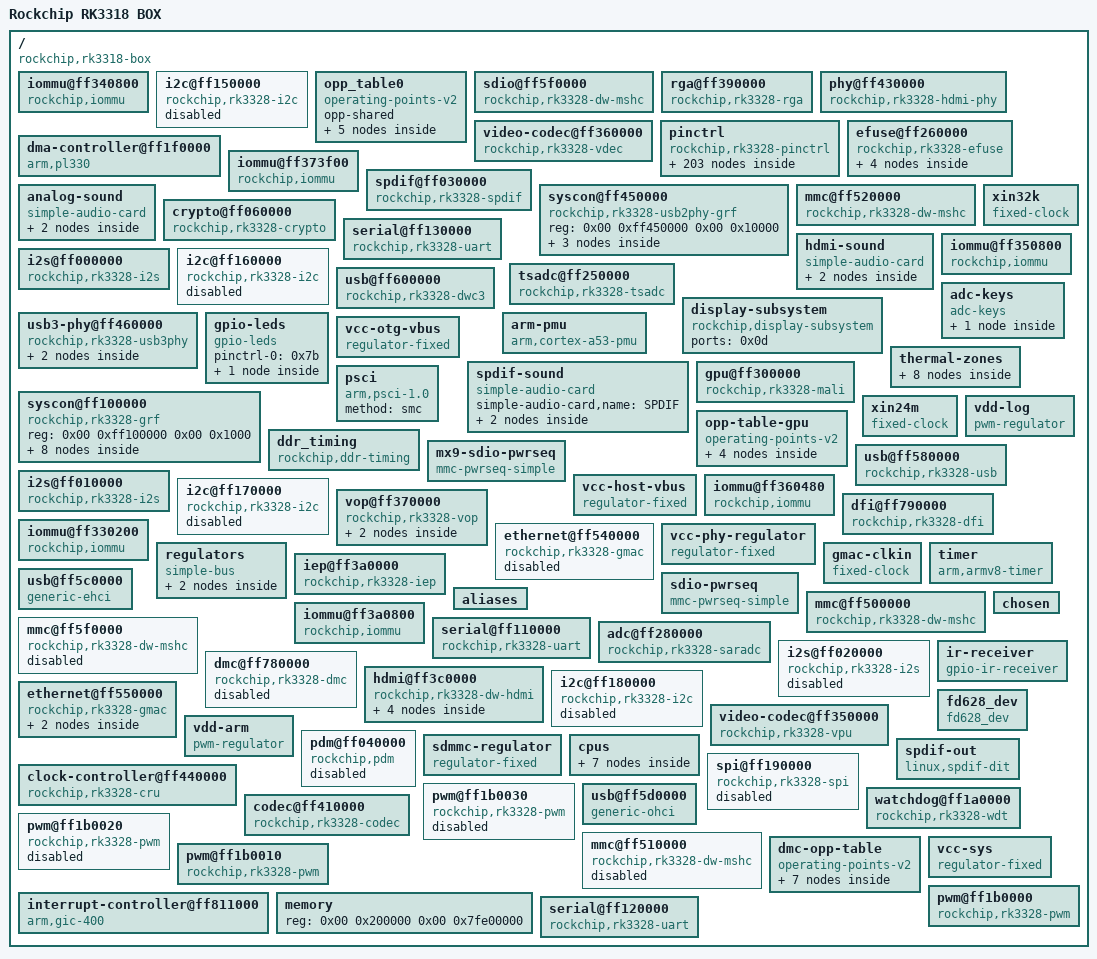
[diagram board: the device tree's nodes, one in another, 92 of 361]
/dts-v1/;

/ {
	#address-cells = <0x02>;
	model = "Rockchip RK3318 BOX";
	serial-number = "0ee56abe064fdcdd";
	#size-cells = <0x02>;
	interrupt-parent = <0x01>;
	compatible = "rockchip,rk3318-box\0rockchip,rk3328-box\0rockchip,rk3328";

	iommu@ff340800 {
		clock-names = "aclk\0iface";
		interrupts = <0x00 0x62 0x04>;
		clocks = <0x02 0x8f 0x02 0x146>;
		#iommu-cells = <0x00>;
		compatible = "rockchip,iommu";
		status = "okay";
		reg = <0x00 0xff340800 0x00 0x40>;
		phandle = <0x9a>;
	};

	i2c@ff150000 {
		pinctrl-names = "default";
		#address-cells = <0x01>;
		pinctrl-0 = <0x27>;
		clock-names = "i2c\0pclk";
		interrupts = <0x00 0x24 0x04>;
		clocks = <0x02 0x37 0x02 0xcd>;
		#size-cells = <0x00>;
		compatible = "rockchip,rk3328-i2c\0rockchip,rk3399-i2c";
		status = "disabled";
		reg = <0x00 0xff150000 0x00 0x1000>;
		phandle = <0x89>;
	};

	opp_table0 {
		opp-shared;
		compatible = "operating-points-v2";
		phandle = <0x04>;

		opp-1200000000 {
			opp-microvolt = <0x124f80>;
			opp-hz = <0x00 0x47868c00>;
			status = "disabled";
			clock-latency-ns = <0x9c40>;
		};

		opp-1008000000 {
			opp-microvolt = <0x10c8e0>;
			opp-hz = <0x00 0x3c14dc00>;
			clock-latency-ns = <0x9c40>;
		};

		opp-1296000000 {
			opp-microvolt = <0x137478>;
			opp-hz = <0x00 0x4d3f6400>;
			status = "disabled";
			clock-latency-ns = <0x9c40>;
		};

		opp-816000000 {
			opp-microvolt = <0xf4240>;
			opp-hz = <0x00 0x30a32c00>;
			clock-latency-ns = <0x9c40>;
		};

		opp-600000000 {
			opp-microvolt = <0xe7ef0>;
			opp-hz = <0x00 0x23c34600>;
			opp-suspend;
			clock-latency-ns = <0x9c40>;
		};
	};

	sdio@ff5f0000 {
		fifo-depth = <0x100>;
		pinctrl-names = "default";
		#address-cells = <0x01>;
		supports-sdio;
		pinctrl-0 = <0x108 0x109 0x10a 0x10b>;
		clock-names = "biu\0ciu\0ciu-drive\0ciu-sample";
		cap-sd-highspeed;
		bus-width = <0x04>;
		non-removable;
		resets = <0x02 0x68>;
		cap-sdio-irq;
		interrupts = <0x00 0x04 0x04>;
		clocks = <0x02 0x140 0x02 0x1f 0x02 0x4d 0x02 0x51>;
		num-slots = <0x01>;
		#size-cells = <0x00>;
		keep-power-in-suspend;
		compatible = "rockchip,rk3328-dw-mshc\0rockchip,rk3288-dw-mshc";
		status = "okay";
		disable-wp;
		mmc-pwrseq = <0x107>;
		reg = <0x00 0xff5f0000 0x00 0x4000>;
		phandle = <0x103>;
		max-frequency = <0x8f0d180>;
		reset-names = "reset";
	};

	rga@ff390000 {
		clock-names = "aclk\0hclk\0sclk";
		resets = <0x02 0x88 0x02 0x8a 0x02 0x8b>;
		interrupts = <0x00 0x21 0x04>;
		clocks = <0x02 0x9a 0x02 0x154 0x02 0x45>;
		compatible = "rockchip,rk3328-rga\0rockchip,rk3399-rga";
		reg = <0x00 0xff390000 0x00 0x1000>;
		phandle = <0x9e>;
		reset-names = "core\0axi\0ahb";
	};

	phy@ff430000 {
		nvmem-cells = <0x4b>;
		clock-output-names = "hdmi_phy";
		clock-names = "sysclk\0refoclk\0refpclk";
		interrupts = <0x00 0x53 0x04>;
		clocks = <0x02 0xe4 0x4a 0x02 0x79>;
		#clock-cells = <0x00>;
		#phy-cells = <0x00>;
		compatible = "rockchip,rk3328-hdmi-phy";
		status = "okay";
		nvmem-cell-names = "cpu-version";
		reg = <0x00 0xff430000 0x00 0x10000>;
		phandle = <0x44>;
	};

	video-codec@ff360000 {
		power-domains = <0x3e 0x05>;
		iommus = <0x40>;
		clock-names = "axi\0ahb\0cabac\0core";
		assigned-clocks = <0x02 0x8b 0x02 0x41 0x02 0x42>;
		assigned-clock-rates = <0x17d78400 0x17d78400 0x11e1a300>;
		interrupts = <0x00 0x07 0x04>;
		clocks = <0x02 0x8b 0x02 0x142 0x02 0x41 0x02 0x42>;
		compatible = "rockchip,rk3328-vdec\0rockchip,rk3399-vdec";
		reg = <0x00 0xff360000 0x00 0x480>;
		phandle = <0x9c>;
	};

	pinctrl {
		pinctrl-names = "default";
		#address-cells = <0x02>;
		pinctrl-0 = <0x67>;
		#size-cells = <0x02>;
		compatible = "rockchip,rk3328-pinctrl";
		ranges;
		rockchip,grf = <0x38>;
		phandle = <0xaf>;

		i2c3 {

			i2c3-xfer {
				rockchip,pins = <0x00 0x05 0x02 0x68 0x00 0x06 0x02 0x68>;
				phandle = <0x2a>;
			};

			i2c3-pins {
				rockchip,pins = <0x00 0x05 0x00 0x68 0x00 0x06 0x00 0x68>;
				phandle = <0xb5>;
			};
		};

		clk_32k {

			clk-32k-out {
				rockchip,pins = <0x01 0x1c 0x01 0x68>;
				phandle = <0x67>;
			};
		};

		pcfg-pull-none-12ma {
			drive-strength = <0x0c>;
			bias-disable;
			phandle = <0x6f>;
		};

		ir {

			ir-int {
				rockchip,pins = <0x02 0x02 0x00 0x68>;
				phandle = <0x7d>;
			};
		};

		i2s1 {

			i2s1-lrcktx {
				rockchip,pins = <0x02 0x11 0x01 0x68>;
				phandle = <0xc8>;
			};

			i2s1-lrckrx {
				rockchip,pins = <0x02 0x10 0x01 0x68>;
				phandle = <0xc7>;
			};

			i2s1-sleep {
				rockchip,pins = <0x02 0x0f 0x00 0x69 0x02 0x10 0x00 0x69 0x02 0x11 0x00 0x69 0x02 0x12 0x00 0x69 0x02 0x13 0x00 0x69 0x02 0x14 0x00 0x69 0x02 0x15 0x00 0x69 0x02 0x16 0x00 0x69 0x02 0x17 0x00 0x69>;
				phandle = <0xce>;
			};

			i2s1-mclk {
				rockchip,pins = <0x02 0x0f 0x01 0x68>;
				phandle = <0xc5>;
			};

			i2s1-sdio3 {
				rockchip,pins = <0x02 0x16 0x01 0x68>;
				phandle = <0xcd>;
			};

			i2s1-sdio1 {
				rockchip,pins = <0x02 0x14 0x01 0x68>;
				phandle = <0xcb>;
			};

			i2s1-sdo {
				rockchip,pins = <0x02 0x17 0x01 0x68>;
				phandle = <0xca>;
			};

			i2s1-sdi {
				rockchip,pins = <0x02 0x13 0x01 0x68>;
				phandle = <0xc9>;
			};

			i2s1-sdio2 {
				rockchip,pins = <0x02 0x15 0x01 0x68>;
				phandle = <0xcc>;
			};

			i2s1-sclk {
				rockchip,pins = <0x02 0x12 0x01 0x68>;
				phandle = <0xc6>;
			};
		};

		mx9pro-sdmmc0ext {

			mx9-sdmmc0ext-clk {
				rockchip,pins = <0x03 0x02 0x03 0x104>;
				phandle = <0x108>;
			};

			mx9-sdmmc0ext-dectn {
				rockchip,pins = <0x03 0x01 0x03 0x105>;
				phandle = <0x10a>;
			};

			mx9-sdmmc0ext-bus4 {
				rockchip,pins = <0x03 0x04 0x03 0x105 0x03 0x05 0x03 0x105 0x03 0x06 0x03 0x105 0x03 0x07 0x03 0x105>;
				phandle = <0x10b>;
			};

			mx9-sdmmc0ext-cmd {
				rockchip,pins = <0x03 0x00 0x03 0x105>;
				phandle = <0x109>;
			};
		};

		i2c1 {

			i2c1-xfer {
				rockchip,pins = <0x02 0x04 0x02 0x68 0x02 0x05 0x02 0x68>;
				phandle = <0x28>;
			};
		};

		usb3 {

			usb30-host-drv {
				rockchip,pins = <0x00 0x00 0x00 0x68>;
				phandle = <0x76>;
			};
		};

		gpio@ff230000 {
			gpio-controller;
			interrupts = <0x00 0x35 0x04>;
			clocks = <0x02 0xca>;
			compatible = "rockchip,gpio-bank";
			#interrupt-cells = <0x02>;
			reg = <0x00 0xff230000 0x00 0x100>;
			phandle = <0x7c>;
			#gpio-cells = <0x02>;
			interrupt-controller;
		};

		cif-1 {

			dvp-d2d9-m1 {
				rockchip,pins = <0x03 0x04 0x02 0x68 0x03 0x05 0x02 0x68 0x03 0x06 0x02 0x68 0x03 0x07 0x02 0x68 0x03 0x08 0x02 0x68 0x02 0x10 0x04 0x68 0x02 0x11 0x04 0x68 0x02 0x12 0x04 0x68 0x03 0x01 0x02 0x68 0x03 0x00 0x02 0x68 0x02 0x0f 0x04 0x68 0x03 0x02 0x02 0x68>;
				phandle = <0xf9>;
			};
		};

		spdif-2 {

			spdifm2-tx {
				rockchip,pins = <0x00 0x02 0x02 0x68>;
				phandle = <0xde>;
			};
		};

		pcfg-pull-down-4ma {
			drive-strength = <0x04>;
			bias-pull-down;
			phandle = <0xb1>;
		};

		spi0-2 {

			spi0m2-tx {
				rockchip,pins = <0x03 0x01 0x04 0x6a>;
				phandle = <0x2c>;
			};

			spi0m2-clk {
				rockchip,pins = <0x03 0x00 0x04 0x6a>;
				phandle = <0x2b>;
			};

			spi0m2-rx {
				rockchip,pins = <0x03 0x02 0x04 0x6a>;
				phandle = <0x2d>;
			};

			spi0m2-cs0 {
				rockchip,pins = <0x03 0x08 0x03 0x6a>;
				phandle = <0x2e>;
			};
		};

		pcfg-pull-none-2ma {
			drive-strength = <0x02>;
			bias-disable;
			phandle = <0x71>;
		};

		sdmmc0-0 {

			sdmmc0m0-pwren {
				rockchip,pins = <0x02 0x07 0x01 0x6b>;
				phandle = <0xdf>;
			};

			sdmmc0m0-pin {
				rockchip,pins = <0x02 0x07 0x00 0x6b>;
				phandle = <0xe0>;
			};
		};

		spdif-0 {

			spdifm0-tx {
				rockchip,pins = <0x00 0x1b 0x01 0x68>;
				phandle = <0x13>;
			};
		};

		tsadc_pin {

			tsadc-pin {
				rockchip,pins = <0x02 0x0d 0x00 0x68>;
				phandle = <0xf7>;
			};

			tsadc-int {
				rockchip,pins = <0x02 0x0d 0x02 0x68>;
				phandle = <0xf6>;
			};
		};

		pcfg-pull-down {
			bias-pull-down;
			phandle = <0x72>;
		};

		mx9-pcfg-pull-none {
			bias-disable;
			phandle = <0x106>;
		};

		gmac-1 {

			rgmiim1-pins {
				rockchip,pins = <0x01 0x0c 0x02 0x6c 0x01 0x0d 0x02 0x6e 0x01 0x13 0x02 0x6e 0x01 0x19 0x02 0x6c 0x01 0x15 0x02 0x6e 0x01 0x16 0x02 0x6e 0x01 0x17 0x02 0x6e 0x01 0x0a 0x02 0x6e 0x01 0x0b 0x02 0x6e 0x01 0x08 0x02 0x6c 0x01 0x09 0x02 0x6c 0x01 0x0e 0x02 0x6e 0x01 0x0f 0x02 0x6e 0x01 0x10 0x02 0x6c 0x01 0x11 0x02 0x6c 0x00 0x08 0x01 0x6c 0x00 0x0c 0x01 0x6c 0x00 0x18 0x01 0x6e 0x00 0x10 0x01 0x6c 0x00 0x11 0x01 0x6c 0x00 0x17 0x01 0x6c 0x00 0x16 0x01 0x6c>;
				phandle = <0xf1>;
			};

			rmiim1-pins {
				rockchip,pins = <0x01 0x13 0x02 0x71 0x01 0x19 0x02 0x6f 0x01 0x15 0x02 0x71 0x01 0x18 0x02 0x71 0x01 0x16 0x02 0x71 0x01 0x17 0x02 0x71 0x01 0x0a 0x02 0x71 0x01 0x0b 0x02 0x71 0x01 0x08 0x02 0x6f 0x01 0x09 0x02 0x6f 0x00 0x0b 0x01 0x68 0x00 0x0c 0x01 0x68 0x00 0x18 0x01 0x68 0x00 0x13 0x01 0x68 0x00 0x10 0x01 0x68 0x00 0x11 0x01 0x68>;
				phandle = <0xf2>;
			};
		};

		spi0-0 {

			spi0m0-cs0 {
				rockchip,pins = <0x02 0x0b 0x01 0x6a>;
				phandle = <0xbc>;
			};

			spi0m0-cs1 {
				rockchip,pins = <0x02 0x0c 0x01 0x6a>;
				phandle = <0xbf>;
			};

			spi0m0-clk {
				rockchip,pins = <0x02 0x08 0x01 0x6a>;
				phandle = <0xbb>;
			};

			spi0m0-tx {
				rockchip,pins = <0x02 0x09 0x01 0x6a>;
				phandle = <0xbd>;
			};

			spi0m0-rx {
				rockchip,pins = <0x02 0x0a 0x01 0x6a>;
				phandle = <0xbe>;
			};
		};

		i2s2-0 {

			i2s2m0-mclk {
				rockchip,pins = <0x01 0x15 0x01 0x68>;
				phandle = <0xcf>;
			};

			i2s2m0-lrcktx {
				rockchip,pins = <0x01 0x17 0x01 0x68>;
				phandle = <0xd2>;
			};

			i2s2m0-sdi {
				rockchip,pins = <0x01 0x18 0x01 0x68>;
				phandle = <0xd3>;
			};

			i2s2m0-lrckrx {
				rockchip,pins = <0x01 0x1a 0x01 0x68>;
				phandle = <0xd1>;
			};

			i2s2m0-sleep {
				rockchip,pins = <0x01 0x15 0x00 0x69 0x01 0x16 0x00 0x69 0x01 0x1a 0x00 0x69 0x01 0x17 0x00 0x69 0x01 0x18 0x00 0x69 0x01 0x19 0x00 0x69>;
				phandle = <0xd5>;
			};

			i2s2m0-sclk {
				rockchip,pins = <0x01 0x16 0x01 0x68>;
				phandle = <0xd0>;
			};

			i2s2m0-sdo {
				rockchip,pins = <0x01 0x19 0x01 0x68>;
				phandle = <0xd4>;
			};
		};

		hdmi_i2c {

			hdmii2c-xfer {
				rockchip,pins = <0x00 0x05 0x01 0x68 0x00 0x06 0x01 0x68>;
				phandle = <0x46>;
			};
		};

		gpio@ff240000 {
			gpio-controller;
			interrupts = <0x00 0x36 0x04>;
			clocks = <0x02 0xcb>;
			compatible = "rockchip,gpio-bank";
			#interrupt-cells = <0x02>;
			reg = <0x00 0xff240000 0x00 0x100>;
			phandle = <0x60>;
			#gpio-cells = <0x02>;
			interrupt-controller;
		};

		sdmmc1 {

			sdmmc1-cmd {
				rockchip,pins = <0x01 0x0d 0x01 0x6d>;
				phandle = <0x55>;
			};

			sdmmc1-pins {
				rockchip,pins = <0x01 0x0c 0x00 0x6b 0x01 0x0d 0x00 0x6b 0x01 0x0e 0x00 0x6b 0x01 0x0f 0x00 0x6b 0x01 0x10 0x00 0x6b 0x01 0x11 0x00 0x6b 0x01 0x12 0x00 0x6b 0x01 0x13 0x00 0x6b 0x01 0x14 0x00 0x6b>;
				phandle = <0xec>;
			};

			sdmmc1-bus1 {
				rockchip,pins = <0x01 0x0e 0x01 0x6d>;
				phandle = <0xeb>;
			};

			sdmmc1-clk {
				rockchip,pins = <0x01 0x0c 0x01 0x6c>;
				phandle = <0x56>;
			};

			sdmmc1-bus4 {
				rockchip,pins = <0x01 0x0e 0x01 0x6d 0x01 0x0f 0x01 0x6d 0x01 0x10 0x01 0x6d 0x01 0x11 0x01 0x6d>;
				phandle = <0x54>;
			};

			sdmmc1-pwren {
				rockchip,pins = <0x01 0x12 0x01 0x6d>;
				phandle = <0xe8>;
			};

			sdmmc1-dectn {
				rockchip,pins = <0x01 0x13 0x01 0x6d>;
				phandle = <0xea>;
			};

			sdmmc1-wrprt {
				rockchip,pins = <0x01 0x14 0x01 0x6d>;
				phandle = <0xe9>;
			};
		};

		pcfg-pull-none-8ma {
			drive-strength = <0x08>;
			bias-disable;
			phandle = <0x6c>;
		};

		leds {

			working-led {
				rockchip,pins = <0x02 0x17 0x00 0x71>;
				phandle = <0x7b>;
			};
		};

		pwm1 {

			pwm1-pin {
				rockchip,pins = <0x02 0x05 0x01 0x68>;
				phandle = <0x30>;
			};
		};

		tsadc {

			otp-pin {
				rockchip,pins = <0x02 0x0d 0x00 0x68>;
				phandle = <0x36>;
			};

			otp-out {
				rockchip,pins = <0x02 0x0d 0x01 0x68>;
				phandle = <0x37>;
			};
		};

		pwmir {

			pwmir-pin {
				rockchip,pins = <0x02 0x02 0x01 0x68>;
				phandle = <0x32>;
			};
		};

		uart2-1 {

			uart2m1-xfer {
				rockchip,pins = <0x02 0x00 0x01 0x68 0x02 0x01 0x01 0x6a>;
				phandle = <0x26>;
			};
		};

		uart0 {

			uart0-rts-pin {
				rockchip,pins = <0x01 0x0a 0x00 0x68>;
				phandle = <0xb8>;
			};

			uart0-cts {
				rockchip,pins = <0x01 0x0b 0x01 0x68>;
				phandle = <0x21>;
			};

			uart0-rts {
				rockchip,pins = <0x01 0x0a 0x01 0x68>;
				phandle = <0x22>;
			};

			uart0-xfer {
				rockchip,pins = <0x01 0x09 0x01 0x68 0x01 0x08 0x01 0x6a>;
				phandle = <0x20>;
			};
		};

		emmc {

			emmc-clk {
				rockchip,pins = <0x03 0x15 0x02 0x6f>;
				phandle = <0x57>;
			};

			emmc-bus1 {
				rockchip,pins = <0x00 0x07 0x02 0x70>;
				phandle = <0xef>;
			};

			emmc-bus8 {
				rockchip,pins = <0x00 0x07 0x02 0x70 0x02 0x1c 0x02 0x70 0x02 0x1d 0x02 0x70 0x02 0x1e 0x02 0x70 0x02 0x1f 0x02 0x70 0x03 0x10 0x02 0x70 0x03 0x11 0x02 0x70 0x03 0x12 0x02 0x70>;
				phandle = <0x59>;
			};

			emmc-bus4 {
				rockchip,pins = <0x00 0x07 0x02 0x70 0x02 0x1c 0x02 0x70 0x02 0x1d 0x02 0x70 0x02 0x1e 0x02 0x70>;
				phandle = <0xf0>;
			};

			emmc-pwren {
				rockchip,pins = <0x03 0x16 0x02 0x68>;
				phandle = <0xed>;
			};

			emmc-cmd {
				rockchip,pins = <0x03 0x13 0x02 0x70>;
				phandle = <0x58>;
			};

			emmc-rstnout {
				rockchip,pins = <0x03 0x14 0x02 0x68>;
				phandle = <0xee>;
			};
		};

		pcfg-output-high {
			output-high;
			phandle = <0xb2>;
		};

		pcfg-pull-up {
			phandle = <0x6a>;
			bias-pull-up;
		};

		sdmmc0ext {

			sdmmc0ext-clk {
				rockchip,pins = <0x03 0x02 0x03 0x6e>;
				phandle = <0x61>;
			};

			sdmmc0ext-bus4 {
				rockchip,pins = <0x03 0x04 0x03 0x6b 0x03 0x05 0x03 0x6b 0x03 0x06 0x03 0x6b 0x03 0x07 0x03 0x6b>;
				phandle = <0x64>;
			};

			sdmmc0ext-wrprt {
				rockchip,pins = <0x03 0x03 0x03 0x6b>;
				phandle = <0xe5>;
			};

			sdmmc0ext-pins {
				rockchip,pins = <0x03 0x00 0x00 0x6b 0x03 0x01 0x00 0x6b 0x03 0x02 0x00 0x6b 0x03 0x03 0x00 0x6b 0x03 0x04 0x00 0x6b 0x03 0x05 0x00 0x6b 0x03 0x06 0x00 0x6b 0x03 0x07 0x00 0x6b>;
				phandle = <0xe7>;
			};

			sdmmc0ext-bus1 {
				rockchip,pins = <0x03 0x04 0x03 0x6b>;
				phandle = <0xe6>;
			};

			sdmmc0ext-cmd {
				rockchip,pins = <0x03 0x00 0x03 0x6b>;
				phandle = <0x62>;
			};

			sdmmc0ext-dectn {
				rockchip,pins = <0x03 0x01 0x03 0x6b>;
				phandle = <0x63>;
			};
		};

		mx9-pcfg-pull-up-4ma {
			drive-strength = <0x04>;
			phandle = <0x105>;
			bias-pull-up;
		};

		pcfg-input {
			phandle = <0xb4>;
			input-enable;
		};

		pcfg-pull-up-2ma {
			drive-strength = <0x02>;
			phandle = <0xb0>;
			bias-pull-up;
		};

		i2c2 {

			i2c2-xfer {
				rockchip,pins = <0x02 0x0d 0x01 0x68 0x02 0x0e 0x01 0x68>;
				phandle = <0x29>;
			};
		};

		pmic {

			pmic-int-l {
				rockchip,pins = <0x02 0x06 0x00 0x6a>;
				phandle = <0xfa>;
			};
		};

		pcfg-pull-none {
			bias-disable;
			phandle = <0x68>;
		};

		pcfg-pull-none-4ma {
			drive-strength = <0x04>;
			bias-disable;
			phandle = <0x6e>;
		};

		gpio@ff210000 {
			gpio-controller;
			interrupts = <0x00 0x33 0x04>;
			clocks = <0x02 0xc8>;
			compatible = "rockchip,gpio-bank";
			#interrupt-cells = <0x02>;
			reg = <0x00 0xff210000 0x00 0x100>;
			phandle = <0x74>;
			#gpio-cells = <0x02>;
			interrupt-controller;
		};

		sdio-pwrseq {

			wifi-enable-h {
				rockchip,pins = <0x01 0x12 0x00 0x6e>;
				phandle = <0x7e>;
			};
		};

		pdm-0 {

			pdmm0-sdi3 {
				rockchip,pins = <0x02 0x16 0x02 0x68>;
				phandle = <0x18>;
			};

			pdmm0-sdi1 {
				rockchip,pins = <0x02 0x14 0x02 0x68>;
				phandle = <0x16>;
			};

			pdmm0-sdi2-sleep {
				rockchip,pins = <0x02 0x15 0x00 0x69>;
				phandle = <0x1c>;
			};

			pdmm0-fsync {
				rockchip,pins = <0x02 0x17 0x02 0x68>;
				phandle = <0xb6>;
			};

			pdmm0-sdi3-sleep {
				rockchip,pins = <0x02 0x16 0x00 0x69>;
				phandle = <0x1d>;
			};

			pdmm0-sdi2 {
				rockchip,pins = <0x02 0x15 0x02 0x68>;
				phandle = <0x17>;
			};

			pdmm0-sdi0 {
				rockchip,pins = <0x02 0x13 0x02 0x68>;
				phandle = <0x15>;
			};

			pdmm0-sdi0-sleep {
				rockchip,pins = <0x02 0x13 0x00 0x69>;
				phandle = <0x1a>;
			};

			pdmm0-clk-sleep {
				rockchip,pins = <0x02 0x12 0x00 0x69>;
				phandle = <0x19>;
			};

			pdmm0-clk {
				rockchip,pins = <0x02 0x12 0x02 0x68>;
				phandle = <0x14>;
			};

			pdmm0-fsync-sleep {
				rockchip,pins = <0x02 0x17 0x00 0x69>;
				phandle = <0xb7>;
			};

			pdmm0-sdi1-sleep {
				rockchip,pins = <0x02 0x14 0x00 0x69>;
				phandle = <0x1b>;
			};
		};

		i2c0 {

			i2c0-xfer {
				rockchip,pins = <0x02 0x18 0x01 0x68 0x02 0x19 0x01 0x68>;
				phandle = <0x27>;
			};
		};

		usb2 {

			usb20-host-drv {
				rockchip,pins = <0x00 0x02 0x00 0x68>;
				phandle = <0x78>;
			};
		};

		sdmmc0-1 {

			sdmmc0m1-pwren {
				rockchip,pins = <0x00 0x1e 0x03 0x6b>;
				phandle = <0xe1>;
			};

			sdmmc0m1-pin {
				rockchip,pins = <0x00 0x1e 0x00 0x6b>;
				phandle = <0x75>;
			};
		};

		cif-0 {

			dvp-d2d9-m0 {
				rockchip,pins = <0x03 0x04 0x02 0x68 0x03 0x05 0x02 0x68 0x03 0x06 0x02 0x68 0x03 0x07 0x02 0x68 0x03 0x08 0x02 0x68 0x03 0x09 0x02 0x68 0x03 0x0a 0x02 0x68 0x03 0x0b 0x02 0x68 0x03 0x01 0x02 0x68 0x03 0x00 0x02 0x68 0x03 0x03 0x02 0x68 0x03 0x02 0x02 0x68>;
				phandle = <0xf8>;
			};
		};

		spdif-1 {

			spdifm1-tx {
				rockchip,pins = <0x02 0x11 0x02 0x68>;
				phandle = <0xdd>;
			};
		};

		pcfg-input-high {
			phandle = <0x69>;
			bias-pull-up;
			input-enable;
		};

		pcfg-pull-up-8ma {
			drive-strength = <0x08>;
			phandle = <0x6d>;
			bias-pull-up;
		};

		spi0-1 {

			spi0m1-cs0 {
				rockchip,pins = <0x03 0x1a 0x02 0x6a>;
				phandle = <0xc1>;
			};

			spi0m1-tx {
				rockchip,pins = <0x03 0x19 0x02 0x6a>;
				phandle = <0xc2>;
			};

			spi0m1-rx {
				rockchip,pins = <0x03 0x18 0x02 0x6a>;
				phandle = <0xc3>;
			};

			spi0m1-cs1 {
				rockchip,pins = <0x03 0x1b 0x02 0x6a>;
				phandle = <0xc4>;
			};

			spi0m1-clk {
				rockchip,pins = <0x03 0x17 0x02 0x6a>;
				phandle = <0xc0>;
			};
		};

		mx9-wifi-enable-h {
			rockchip,pins = <0x03 0x08 0x00 0x106>;
			phandle = <0x10c>;
		};

		i2s2-1 {

			i2s2m1-mclk {
				rockchip,pins = <0x01 0x15 0x01 0x68>;
				phandle = <0xd6>;
			};

			i2s2m1-sdo {
				rockchip,pins = <0x03 0x01 0x06 0x68>;
				phandle = <0xdb>;
			};

			i2s2m1-lrcktx {
				rockchip,pins = <0x03 0x08 0x04 0x68>;
				phandle = <0xd9>;
			};

			i2s2m1-sdi {
				rockchip,pins = <0x03 0x02 0x06 0x68>;
				phandle = <0xda>;
			};

			i2sm1-lrckrx {
				rockchip,pins = <0x03 0x08 0x06 0x68>;
				phandle = <0xd8>;
			};

			i2s2m1-sleep {
				rockchip,pins = <0x01 0x15 0x00 0x69 0x03 0x00 0x00 0x69 0x03 0x08 0x00 0x69 0x03 0x02 0x00 0x69 0x03 0x01 0x00 0x69>;
				phandle = <0xdc>;
			};

			i2s2m1-sclk {
				rockchip,pins = <0x03 0x00 0x06 0x68>;
				phandle = <0xd7>;
			};
		};

		pcfg-pull-up-12ma {
			drive-strength = <0x0c>;
			phandle = <0x70>;
			bias-pull-up;
		};

		hdmi_pin {

			hdmi-cec {
				rockchip,pins = <0x00 0x03 0x01 0x68>;
				phandle = <0x45>;
			};

			hdmi-hpd {
				rockchip,pins = <0x00 0x04 0x01 0x72>;
				phandle = <0x47>;
			};
		};

		pcfg-output-low {
			phandle = <0xb3>;
			output-low;
		};

		gmac2phy {

			fephyled-speed10 {
				rockchip,pins = <0x00 0x1e 0x01 0x68>;
				phandle = <0xf3>;
			};

			fephyled-linkm1 {
				rockchip,pins = <0x02 0x18 0x02 0x68>;
				phandle = <0x5d>;
			};

			fephyled-duplex {
				rockchip,pins = <0x00 0x1e 0x02 0x68>;
				phandle = <0xf4>;
			};

			fephyled-rxm1 {
				rockchip,pins = <0x02 0x19 0x02 0x68>;
				phandle = <0x5c>;
			};

			fephyled-txm1 {
				rockchip,pins = <0x02 0x19 0x03 0x68>;
				phandle = <0xf5>;
			};
		};

		pwm2 {

			pwm2-pin {
				rockchip,pins = <0x02 0x06 0x01 0x68>;
				phandle = <0x31>;
			};
		};

		gpio@ff220000 {
			gpio-controller;
			interrupts = <0x00 0x34 0x04>;
			clocks = <0x02 0xc9>;
			compatible = "rockchip,gpio-bank";
			#interrupt-cells = <0x02>;
			reg = <0x00 0xff220000 0x00 0x100>;
			phandle = <0x4d>;
			#gpio-cells = <0x02>;
			interrupt-controller;
		};

		mx9-pcfg-pull-none-4ma {
			drive-strength = <0x04>;
			bias-disable;
			phandle = <0x104>;
		};

		uart1 {

			uart1-cts {
				rockchip,pins = <0x03 0x07 0x04 0x68>;
				phandle = <0x24>;
			};

			uart1-rts-pin {
				rockchip,pins = <0x03 0x05 0x00 0x68>;
				phandle = <0xb9>;
			};

			uart1-rts {
				rockchip,pins = <0x03 0x05 0x04 0x68>;
				phandle = <0x25>;
			};

			uart1-xfer {
				rockchip,pins = <0x03 0x04 0x04 0x68 0x03 0x06 0x04 0x6a>;
				phandle = <0x23>;
			};
		};

		sdmmc0 {

			sdmmc0-pins {
				rockchip,pins = <0x01 0x06 0x00 0x6b 0x01 0x04 0x00 0x6b 0x01 0x05 0x00 0x6b 0x01 0x07 0x00 0x6b 0x01 0x03 0x00 0x6b 0x01 0x02 0x00 0x6b 0x01 0x01 0x00 0x6b 0x01 0x00 0x00 0x6b>;
				phandle = <0xe4>;
			};

			sdmmc0-bus1 {
				rockchip,pins = <0x01 0x00 0x01 0x6d>;
				phandle = <0xe3>;
			};

			sdmmc0-dectn {
				rockchip,pins = <0x01 0x05 0x01 0x6b>;
				phandle = <0x50>;
			};

			sdmmc0-bus4 {
				rockchip,pins = <0x01 0x00 0x01 0x6d 0x01 0x01 0x01 0x6d 0x01 0x02 0x01 0x6d 0x01 0x03 0x01 0x6d>;
				phandle = <0x51>;
			};

			sdmmc0-wrprt {
				rockchip,pins = <0x01 0x07 0x01 0x6b>;
				phandle = <0xe2>;
			};

			sdmmc0-cmd {
				rockchip,pins = <0x01 0x04 0x01 0x6d>;
				phandle = <0x4f>;
			};

			sdmmc0-clk {
				rockchip,pins = <0x01 0x06 0x01 0x6c>;
				phandle = <0x4e>;
			};
		};

		pcfg-pull-up-4ma {
			drive-strength = <0x04>;
			phandle = <0x6b>;
			bias-pull-up;
		};

		pwm0 {

			pwm0-pin {
				rockchip,pins = <0x02 0x04 0x01 0x68>;
				phandle = <0x2f>;
			};
		};

		uart2-0 {

			uart2m0-xfer {
				rockchip,pins = <0x01 0x00 0x02 0x68 0x01 0x01 0x02 0x6a>;
				phandle = <0xba>;
			};
		};

		wireless-wlan {

			sdio-host-wake {
				rockchip,pins = <0x01 0x13 0x00 0x68>;
				phandle = <0xfb>;
			};

			sdio-host-wake-ext {
				rockchip,pins = <0x03 0x01 0x00 0x68>;
				phandle = <0xfc>;
			};
		};
	};

	efuse@ff260000 {
		#address-cells = <0x01>;
		clock-names = "pclk_efuse";
		clocks = <0x02 0x3e>;
		#size-cells = <0x01>;
		compatible = "rockchip,rk3328-efuse";
		rockchip,efuse-size = <0x20>;
		reg = <0x00 0xff260000 0x00 0x50>;
		phandle = <0x95>;

		id@7 {
			reg = <0x07 0x10>;
			phandle = <0x96>;
		};

		cpu-version@1a {
			bits = <0x03 0x03>;
			reg = <0x1a 0x01>;
			phandle = <0x4b>;
		};

		logic-leakage@19 {
			reg = <0x19 0x01>;
			phandle = <0x98>;
		};

		cpu-leakage@17 {
			reg = <0x17 0x01>;
			phandle = <0x97>;
		};
	};

	dma-controller@ff1f0000 {
		clock-names = "apb_pclk";
		interrupts = <0x00 0x00 0x04 0x00 0x01 0x04>;
		clocks = <0x02 0x86>;
		arm,pl330-periph-burst;
		compatible = "arm,pl330\0arm,primecell";
		reg = <0x00 0xff1f0000 0x00 0x4000>;
		phandle = <0x12>;
		#dma-cells = <0x01>;
	};

	iommu@ff373f00 {
		clock-names = "aclk\0iface";
		interrupts = <0x00 0x20 0x04>;
		clocks = <0x02 0x91 0x02 0x13b>;
		#iommu-cells = <0x00>;
		compatible = "rockchip,iommu";
		status = "okay";
		reg = <0x00 0xff373f00 0x00 0x100>;
		phandle = <0x41>;
	};

	spdif@ff030000 {
		pinctrl-names = "default";
		pinctrl-0 = <0x13>;
		clock-names = "mclk\0hclk";
		interrupts = <0x00 0x1d 0x04>;
		clocks = <0x02 0x2e 0x02 0x13a>;
		dma-names = "tx";
		#sound-dai-cells = <0x00>;
		compatible = "rockchip,rk3328-spdif";
		status = "okay";
		reg = <0x00 0xff030000 0x00 0x1000>;
		phandle = <0x10>;
		dmas = <0x12 0x0a>;
	};

	analog-sound {
		simple-audio-card,name = "ANALOG";
		simple-audio-card,format = "i2s";
		compatible = "simple-audio-card";
		status = "okay";
		phandle = <0x7f>;
		simple-audio-card,mclk-fs = <0x100>;

		simple-audio-card,cpu {
			sound-dai = <0x07>;
		};

		simple-audio-card,codec {
			sound-dai = <0x08>;
		};
	};

	syscon@ff450000 {
		#address-cells = <0x01>;
		#size-cells = <0x01>;
		compatible = "rockchip,rk3328-usb2phy-grf\0syscon\0simple-mfd";
		reg = <0x00 0xff450000 0x00 0x10000>;
		phandle = <0xa2>;

		usb2phy@100 {
			clock-output-names = "usb480m_phy";
			clock-names = "phyclk";
			assigned-clocks = <0x02 0x7b>;
			assigned-clock-parents = <0x4c>;
			clocks = <0x4a>;
			#clock-cells = <0x00>;
			compatible = "rockchip,rk3328-usb2phy";
			status = "okay";
			reg = <0x100 0x10>;
			phandle = <0x4c>;

			host-port {
				interrupts = <0x00 0x3e 0x04>;
				#phy-cells = <0x00>;
				status = "okay";
				interrupt-names = "linestate";
				phandle = <0x5f>;
			};

			otg-port {
				interrupts = <0x00 0x3b 0x04 0x00 0x3c 0x04 0x00 0x3d 0x04>;
				#phy-cells = <0x00>;
				status = "okay";
				interrupt-names = "otg-bvalid\0otg-id\0linestate";
				phandle = <0x5e>;
			};
		};
	};

	mmc@ff520000 {
		fifo-depth = <0x100>;
		pinctrl-names = "default";
		pinctrl-0 = <0x57 0x58 0x59>;
		clock-names = "biu\0ciu\0ciu-drive\0ciu-sample";
		vqmmc-supply = <0x1f>;
		bus-width = <0x08>;
		non-removable;
		no-sdio;
		resets = <0x02 0x6f>;
		interrupts = <0x00 0x0e 0x04>;
		clocks = <0x02 0x13f 0x02 0x23 0x02 0x4c 0x02 0x50>;
		num-slots = <0x01>;
		vmmc-supply = <0x1e>;
		no-sd;
		compatible = "rockchip,rk3328-dw-mshc\0rockchip,rk3288-dw-mshc";
		status = "okay";
		disable-wp;
		reg = <0x00 0xff520000 0x00 0x4000>;
		phandle = <0xa6>;
		max-frequency = <0x8f0d180>;
		cap-mmc-highspeed;
		reset-names = "reset";
		supports-emmc;
	};

	crypto@ff060000 {
		clock-names = "hclk_master\0hclk_slave\0sclk";
		resets = <0x02 0x44>;
		interrupts = <0x00 0x1e 0x04>;
		clocks = <0x02 0x150 0x02 0x151 0x02 0x3b>;
		compatible = "rockchip,rk3328-crypto";
		reg = <0x00 0xff060000 0x00 0x4000>;
		phandle = <0xae>;
		reset-names = "crypto-rst";
	};

	serial@ff130000 {
		reg-io-width = <0x04>;
		pinctrl-names = "default";
		pinctrl-0 = <0x26>;
		clock-names = "baudclk\0apb_pclk";
		interrupts = <0x00 0x39 0x04>;
		clocks = <0x02 0x28 0x02 0xd4>;
		compatible = "rockchip,rk3328-uart\0snps,dw-apb-uart";
		status = "okay";
		reg = <0x00 0xff130000 0x00 0x100>;
		phandle = <0x88>;
		reg-shift = <0x02>;
	};

	hdmi-sound {
		simple-audio-card,name = "HDMI";
		simple-audio-card,format = "i2s";
		compatible = "simple-audio-card";
		status = "okay";
		phandle = <0x81>;
		simple-audio-card,mclk-fs = <0x80>;

		simple-audio-card,cpu {
			sound-dai = <0x0e>;
		};

		simple-audio-card,codec {
			sound-dai = <0x0f>;
		};
	};

	i2s@ff000000 {
		clock-names = "i2s_clk\0i2s_hclk";
		interrupts = <0x00 0x1a 0x04>;
		clocks = <0x02 0x29 0x02 0x137>;
		dma-names = "tx\0rx";
		#sound-dai-cells = <0x00>;
		compatible = "rockchip,rk3328-i2s\0rockchip,rk3066-i2s";
		status = "okay";
		reg = <0x00 0xff000000 0x00 0x1000>;
		phandle = <0x0e>;
		dmas = <0x12 0x0b 0x12 0x0c>;
	};

	xin32k {
		clock-output-names = "xin32k";
		#clock-cells = <0x00>;
		clock-frequency = <0x8000>;
		compatible = "fixed-clock";
		phandle = <0xfe>;
	};

	iommu@ff350800 {
		power-domains = <0x3e 0x08>;
		clock-names = "aclk\0iface";
		interrupts = <0x00 0x0b 0x04>;
		clocks = <0x02 0x8f 0x02 0x146>;
		#iommu-cells = <0x00>;
		compatible = "rockchip,iommu";
		status = "okay";
		reg = <0x00 0xff350800 0x00 0x40>;
		phandle = <0x3f>;
	};

	i2c@ff160000 {
		pinctrl-names = "default";
		#address-cells = <0x01>;
		pinctrl-0 = <0x28>;
		clock-names = "i2c\0pclk";
		interrupts = <0x00 0x25 0x04>;
		clocks = <0x02 0x38 0x02 0xce>;
		#size-cells = <0x00>;
		compatible = "rockchip,rk3328-i2c\0rockchip,rk3399-i2c";
		status = "disabled";
		reg = <0x00 0xff160000 0x00 0x1000>;
		phandle = <0x8a>;
	};

	tsadc@ff250000 {
		pinctrl-names = "init\0default\0sleep";
		pinctrl-2 = <0x36>;
		pinctrl-0 = <0x36>;
		clock-names = "tsadc\0apb_pclk";
		rockchip,hw-tshut-polarity = <0x00>;
		assigned-clocks = <0x02 0x24>;
		assigned-clock-rates = <0xc350>;
		resets = <0x02 0x42>;
		interrupts = <0x00 0x3a 0x04>;
		rockchip,hw-tshut-mode = <0x00>;
		clocks = <0x02 0x24 0x02 0xd5>;
		#thermal-sensor-cells = <0x01>;
		compatible = "rockchip,rk3328-tsadc";
		pinctrl-1 = <0x37>;
		status = "okay";
		reg = <0x00 0xff250000 0x00 0x100>;
		phandle = <0x33>;
		reset-names = "tsadc-apb";
		rockchip,hw-tshut-temp = <0x186a0>;
	};

	display-subsystem {
		ports = <0x0d>;
		compatible = "rockchip,display-subsystem";
		status = "okay";
		phandle = <0x80>;
	};

	usb@ff600000 {
		#address-cells = <0x01>;
		snps,dis_enblslpm_quirk;
		phy-names = "usb2-phy\0usb3-phy";
		clock-names = "ref_clk\0suspend_clk\0bus_clk";
		snps,dis-u2-freeclk-exists-quirk;
		phy_type = "utmi_wide";
		snps,dis_u2_susphy_quirk;
		resets = <0x02 0x78>;
		interrupts = <0x00 0x43 0x04>;
		clocks = <0x02 0x60 0x02 0x61 0x02 0x84>;
		#size-cells = <0x00>;
		compatible = "rockchip,rk3328-dwc3\0snps,dwc3";
		snps,dis_u3_susphy_quirk;
		snps,dis-del-phy-power-chg-quirk;
		status = "okay";
		snps,xhci-trb-ent-quirk;
		phys = <0x65 0x66>;
		reg = <0x00 0xff600000 0x00 0x100000>;
		phandle = <0xad>;
		dr_mode = "host";
		reset-names = "usb3-otg";
		snps,dis-tx-ipgap-linecheck-quirk;
	};

	adc-keys {
		io-channels = <0x73 0x00>;
		poll-interval = <0x64>;
		keyup-threshold-microvolt = <0x1b7740>;
		compatible = "adc-keys";
		phandle = <0xfd>;
		io-channel-names = "buttons";

		recovery {
			press-threshold-microvolt = <0x4268>;
			label = "recovery";
			linux,code = <0x168>;
		};
	};

	usb3-phy@ff460000 {
		#address-cells = <0x02>;
		clock-names = "refclk-usb3otg\0usb3phy-otg\0usb3phy-pipe";
		resets = <0x02 0x7d 0x02 0x7e 0x02 0x7f 0x02 0x7c 0x02 0x9e 0x02 0x9f>;
		interrupts = <0x00 0x4b 0x04 0x00 0x4c 0x04 0x00 0x4d 0x04 0x00 0x4e 0x04>;
		clocks = <0x02 0x5f 0x02 0xe0 0x02 0xe1>;
		#size-cells = <0x02>;
		compatible = "rockchip,rk3328-usb3phy";
		ranges;
		status = "okay";
		interrupt-names = "bvalid\0id\0linestate\0rxdet";
		reg = <0x00 0xff460000 0x00 0x10000>;
		phandle = <0xa3>;
		reset-names = "usb3phy-u2-por\0usb3phy-u3-por\0usb3phy-pipe-mac\0usb3phy-utmi-mac\0usb3phy-utmi-apb\0usb3phy-pipe-apb";

		utmi-port@ff470000 {
			#phy-cells = <0x00>;
			compatible = "rockchip,rk3328-usb3phy-utmi";
			status = "okay";
			reg = <0x00 0xff470000 0x00 0x8000>;
			phandle = <0x65>;
		};

		pipe-port@ff478000 {
			#phy-cells = <0x00>;
			compatible = "rockchip,rk3328-usb3phy-pipe";
			status = "okay";
			reg = <0x00 0xff478000 0x00 0x8000>;
			phandle = <0x66>;
		};
	};

	gpio-leds {
		pinctrl-names = "default";
		pinctrl-0 = <0x7b>;
		compatible = "gpio-leds";
		phandle = <0x102>;

		working {
			linux,default-trigger = "timer";
			default-state = "on";
			gpios = <0x7c 0x17 0x00>;
		};
	};

	arm-pmu {
		interrupt-affinity = <0x09 0x0a 0x0b 0x0c>;
		interrupts = <0x00 0x64 0x04 0x00 0x65 0x04 0x00 0x66 0x04 0x00 0x67 0x04>;
		compatible = "arm,cortex-a53-pmu";
	};

	vcc-otg-vbus {
		regulator-max-microvolt = <0x4c4b40>;
		pinctrl-names = "default";
		gpio = <0x74 0x02 0x00>;
		pinctrl-0 = <0x78>;
		regulator-always-on;
		enable-active-high;
		regulator-min-microvolt = <0x4c4b40>;
		regulator-name = "vcc_otg_vbus";
		compatible = "regulator-fixed";
		phandle = <0x101>;
		vin-supply = <0x77>;
	};

	thermal-zones {

		soc-thermal {
			polling-delay = <0x3e8>;
			polling-delay-passive = <0x14>;
			thermal-sensors = <0x33 0x00>;
			sustainable-power = <0x3e8>;
			phandle = <0x91>;

			trips {

				trip-point0 {
					temperature = <0x13880>;
					hysteresis = <0x7d0>;
					type = "passive";
					phandle = <0x92>;
				};

				soc-crit {
					temperature = <0x186a0>;
					hysteresis = <0x7d0>;
					type = "critical";
					phandle = <0x93>;
				};

				trip-point1 {
					temperature = <0x17318>;
					hysteresis = <0x7d0>;
					type = "passive";
					phandle = <0x34>;
				};
			};

			cooling-maps {

				map0 {
					trip = <0x34>;
					cooling-device = <0x09 0xffffffff 0xffffffff 0x0a 0xffffffff 0xffffffff 0x0b 0xffffffff 0xffffffff 0x0c 0xffffffff 0xffffffff>;
					contribution = <0x1000>;
				};

				map1 {
					trip = <0x34>;
					cooling-device = <0x35 0xffffffff 0xffffffff>;
					contribution = <0x1000>;
				};
			};
		};
	};

	spdif-sound {
		simple-audio-card,name = "SPDIF";
		compatible = "simple-audio-card";
		status = "okay";
		phandle = <0x82>;

		simple-audio-card,cpu {
			sound-dai = <0x10>;
		};

		simple-audio-card,codec {
			sound-dai = <0x11>;
		};
	};

	gpu@ff300000 {
		power-domains = <0x3e 0x01>;
		mali-supply = <0x3b>;
		clock-names = "bus\0core";
		resets = <0x02 0x66>;
		interrupts = <0x00 0x5a 0x04 0x00 0x57 0x04 0x00 0x5d 0x04 0x00 0x58 0x04 0x00 0x59 0x04 0x00 0x5b 0x04 0x00 0x5c 0x04>;
		clocks = <0x02 0x87 0x02 0x87>;
		compatible = "rockchip,rk3328-mali\0arm,mali-450";
		status = "okay";
		interrupt-names = "gp\0gpmmu\0pp\0pp0\0ppmmu0\0pp1\0ppmmu1";
		reg = <0x00 0xff300000 0x00 0x30000>;
		phandle = <0x35>;
		operating-points-v2 = <0x3d>;
		#cooling-cells = <0x02>;
	};

	syscon@ff100000 {
		compatible = "rockchip,rk3328-grf\0syscon\0simple-mfd";
		reg = <0x00 0xff100000 0x00 0x1000>;
		phandle = <0x38>;

		gpio {
			gpio-controller;
			compatible = "rockchip,rk3328-grf-gpio";
			phandle = <0x49>;
			#gpio-cells = <0x02>;
		};

		reboot-mode {
			mode-normal = <0x5242c300>;
			mode-loader = <0x5242c301>;
			mode-bootloader = <0x5242c309>;
			mode-recovery = <0x5242c303>;
			offset = <0x5c8>;
			compatible = "syscon-reboot-mode";
		};

		io-domains {
			vccio1-supply = <0x1e>;
			vccio2-supply = <0x1f>;
			vccio3-supply = <0x1e>;
			vccio4-supply = <0x1f>;
			pmuio-supply = <0x1e>;
			vccio5-supply = <0x1e>;
			vccio6-supply = <0x1e>;
			compatible = "rockchip,rk3328-io-voltage-domain";
			status = "okay";
			phandle = <0x85>;
		};

		power-controller {
			#address-cells = <0x01>;
			#size-cells = <0x00>;
			#power-domain-cells = <0x01>;
			compatible = "rockchip,rk3328-power-controller";
			phandle = <0x3e>;

			power-domain@5 {
				clocks = <0x02 0x8b 0x02 0x142 0x02 0x41 0x02 0x42>;
				#power-domain-cells = <0x00>;
				reg = <0x05>;
			};

			power-domain@1 {
				clocks = <0x02 0x87>;
				#power-domain-cells = <0x00>;
				reg = <0x01>;
			};

			power-domain@8 {
				clocks = <0x02 0x8f 0x02 0x146>;
				#power-domain-cells = <0x00>;
				reg = <0x08>;
			};

			power-domain@6 {
				clocks = <0x02 0x44>;
				#power-domain-cells = <0x00>;
				reg = <0x06>;
			};
		};
	};

	psci {
		method = "smc";
		compatible = "arm,psci-1.0\0arm,psci-0.2";
	};

	xin24m {
		clock-output-names = "xin24m";
		#clock-cells = <0x00>;
		clock-frequency = <0x16e3600>;
		compatible = "fixed-clock";
		phandle = <0x4a>;
	};

	opp-table-gpu {
		compatible = "operating-points-v2";
		phandle = <0x3d>;

		opp-300000000 {
			opp-microvolt = <0x106738>;
			opp-hz = <0x00 0x11e1a300>;
		};

		opp-500000000 {
			opp-microvolt = <0x118c30>;
			opp-hz = <0x00 0x1dcd6500>;
			status = "disabled";
		};

		opp-200000000 {
			opp-microvolt = <0x106738>;
			opp-hz = <0x00 0xbebc200>;
		};

		opp-400000000 {
			opp-microvolt = <0x106738>;
			opp-hz = <0x00 0x17d78400>;
		};
	};

	vdd-log {
		regulator-max-microvolt = <0x13d620>;
		regulator-boot-on;
		regulator-always-on;
		regulator-min-microvolt = <0xdbba0>;
		regulator-name = "vdd_log";
		regulator-ramp-delay = <0x30d4>;
		compatible = "pwm-regulator";
		regulator-settling-time-up-us = <0xfa>;
		phandle = <0x3b>;
		pwms = <0x7a 0x00 0x1388 0x01>;
		pwm-supply = <0x77>;
	};

	ddr_timing {
		cs0_dq24_rx_de-skew = <0x07>;
		lpddr3_drv = <0x28>;
		cs1_dq12_tx_de-skew = <0x08>;
		phy_lpddr4_dq_drv = <0x06>;
		ddr4_odt = <0xf0>;
		phy_lpddr4_ca_drv = <0x14>;
		cs1_dq18_rx_de-skew = <0x07>;
		cs0_dm0_tx_de-skew = <0x0a>;
		cs0_dq23_tx_de-skew = <0x09>;
		cs0_dq29_rx_de-skew = <0x07>;
		ddr3_drv = <0x28>;
		cs1_dq17_tx_de-skew = <0x08>;
		ddr3cas_ddr4a12_de-skew = <0x02>;
		cs1_dm3_tx_de-skew = <0x07>;
		cs1_dq22_rx_de-skew = <0x07>;
		phy_dll_dis_freq = <0x190>;
		cs0_dq28_tx_de-skew = <0x07>;
		ddr4_odt_dis_freq = <0x29a>;
		cs1_dq21_tx_de-skew = <0x08>;
		cs1_dq27_rx_de-skew = <0x07>;
		cs1_dqs3n_tx_de-skew = <0x09>;
		cs1_dq0_rx_de-skew = <0x07>;
		cs0_dqs3_rx_de-skew = <0x07>;
		standby_idle = <0x00>;
		cs0_dq2_rx_de-skew = <0x0c>;
		cs0_dq13_rx_de-skew = <0x0a>;
		cs1_dq26_tx_de-skew = <0x07>;
		ddr3a4_ddr4a5_de-skew = <0x02>;
		cs1_dq31_rx_de-skew = <0x07>;
		cs0_dqs2n_tx_de-skew = <0x0b>;
		cs1_dqs1n_tx_de-skew = <0x09>;
		cs1_dq5_rx_de-skew = <0x07>;
		cs0_dq1_tx_de-skew = <0x0a>;
		cs0_dq12_tx_de-skew = <0x08>;
		cs0_dq7_rx_de-skew = <0x0c>;
		cs0_dq18_rx_de-skew = <0x0a>;
		cs1_dq30_tx_de-skew = <0x07>;
		cs1_dqs1_rx_de-skew = <0x07>;
		cs1_dq11_rx_de-skew = <0x07>;
		cs0_dqs0n_tx_de-skew = <0x0c>;
		ddr4_dll_dis_freq = <0x271>;
		cs1_dq4_tx_de-skew = <0x08>;
		cs0_dq6_tx_de-skew = <0x0a>;
		cs0_dq17_tx_de-skew = <0x09>;
		phy_ddr4_odt_dis_freq = <0x29a>;
		cs0_dq22_rx_de-skew = <0x0a>;
		cs1_dq10_tx_de-skew = <0x08>;
		cs1_dq16_rx_de-skew = <0x07>;
		cs1_dm2_rx_de-skew = <0x07>;
		cs1_dq9_tx_de-skew = <0x07>;
		cs0_dq21_tx_de-skew = <0x09>;
		cs0_dq27_rx_de-skew = <0x07>;
		cs1_dq15_tx_de-skew = <0x07>;
		cs1_dm1_tx_de-skew = <0x07>;
		cs1_dq20_rx_de-skew = <0x07>;
		cs0_dm3_tx_de-skew = <0x07>;
		cs0_dq26_tx_de-skew = <0x07>;
		lpddr4_drv = <0x3c>;
		cs0_dq31_rx_de-skew = <0x07>;
		cs1_dq25_rx_de-skew = <0x07>;
		phy_lpddr3_odt_dis_freq = <0x29a>;
		cs0_dq30_tx_de-skew = <0x07>;
		cs0_dqs1_rx_de-skew = <0x09>;
		cs0_dq0_rx_de-skew = <0x0c>;
		cs0_dq11_rx_de-skew = <0x0a>;
		ddr4_drv = <0x22>;
		cs1_dq24_tx_de-skew = <0x08>;
		ddr3we_ddr4bg1_de-skew = <0x02>;
		ddr3a9_ddr4a0_de-skew = <0x02>;
		cs1_dq3_rx_de-skew = <0x07>;
		cs0_dq10_tx_de-skew = <0x08>;
		cs0_dq5_rx_de-skew = <0x0c>;
		cs0_dq16_rx_de-skew = <0x0a>;
		cs1_dq29_tx_de-skew = <0x07>;
		ddr3ba2_ddr4ba0_de-skew = <0x03>;
		cs1_dq2_tx_de-skew = <0x08>;
		ddr4_speed_bin = <0x0c>;
		cs1_dq8_rx_de-skew = <0x07>;
		cs0_dq4_tx_de-skew = <0x0a>;
		cs0_dq15_tx_de-skew = <0x08>;
		cs0_dq20_rx_de-skew = <0x0a>;
		sr_idle = <0x00>;
		cs1_dq14_rx_de-skew = <0x07>;
		cs1_dm0_rx_de-skew = <0x07>;
		cs1_dq7_tx_de-skew = <0x08>;
		phy_ddr3_odt = <0x03>;
		cs0_dm2_rx_de-skew = <0x0a>;
		cs0_dq9_tx_de-skew = <0x08>;
		phy_ddr3_ck_drv = <0x15>;
		cs0_dq25_rx_de-skew = <0x07>;
		cs1_dq13_tx_de-skew = <0x07>;
		ddr3cke_ddr4a16_de-skew = <0x02>;
		cs1_dq19_rx_de-skew = <0x07>;
		cs0_dm1_tx_de-skew = <0x08>;
		cs1_dqs3p_tx_de-skew = <0x09>;
		cs0_dq24_tx_de-skew = <0x07>;
		ddr3a15_ddr4odt0_de-skew = <0x03>;
		cs1_dq18_tx_de-skew = <0x08>;
		cs1_dq23_rx_de-skew = <0x07>;
		phy_ddr4_ck_drv = <0x13>;
		cs0_dqs2p_tx_de-skew = <0x0b>;
		cs1_dqs1p_tx_de-skew = <0x09>;
		lpddr3_odt_dis_freq = <0x29a>;
		cs0_dq29_tx_de-skew = <0x07>;
		cs1_dq22_tx_de-skew = <0x08>;
		cs1_dq28_rx_de-skew = <0x07>;
		cs0_dqs0p_tx_de-skew = <0x0c>;
		cs1_dq1_rx_de-skew = <0x07>;
		cs0_dq3_rx_de-skew = <0x0c>;
		cs0_dq14_rx_de-skew = <0x0a>;
		phy_lpddr4_ck_cs_drv = <0x06>;
		cs1_dq27_tx_de-skew = <0x07>;
		cs1_dq0_tx_de-skew = <0x08>;
		phy_lpddr3_ck_drv = <0x13>;
		cs1_dq6_rx_de-skew = <0x07>;
		cs0_dq2_tx_de-skew = <0x0a>;
		cs0_dq13_tx_de-skew = <0x08>;
		sr_mc_gate_idle = <0x00>;
		pd_idle = <0x00>;
		cs0_dq8_rx_de-skew = <0x0a>;
		cs0_dq19_rx_de-skew = <0x0a>;
		cs1_dq31_tx_de-skew = <0x07>;
		cs1_dqs2_rx_de-skew = <0x06>;
		ddr3ckn_ddr4ckn_de-skew = <0x0b>;
		cs1_dq12_rx_de-skew = <0x07>;
		cs1_dq5_tx_de-skew = <0x08>;
		cs0_dm0_rx_de-skew = <0x0c>;
		cs0_dq7_tx_de-skew = <0x0a>;
		cs0_dq18_tx_de-skew = <0x09>;
		phy_lpddr4_odt_dis_freq = <0x320>;
		ddr3a8_ddr4a13_de-skew = <0x01>;
		ddr3a7_ddr4a11_de-skew = <0x03>;
		cs0_dq23_rx_de-skew = <0x0a>;
		cs1_dq11_tx_de-skew = <0x07>;
		cs1_dq17_rx_de-skew = <0x07>;
		cs0_dqs3n_tx_de-skew = <0x0a>;
		cs1_dqs2n_tx_de-skew = <0x09>;
		compatible = "rockchip,ddr-timing";
		cs1_dm3_rx_de-skew = <0x07>;
		phy_lpddr3_odt = <0x02>;
		ddr3a5_ddr4a8_de-skew = <0x03>;
		cs0_dq22_tx_de-skew = <0x09>;
		cs0_dq28_rx_de-skew = <0x07>;
		cs1_dq16_tx_de-skew = <0x08>;
		ddr3ckp_ddr4ckp_de-skew = <0x0b>;
		cs1_dm2_tx_de-skew = <0x08>;
		cs1_dq21_rx_de-skew = <0x07>;
		cs0_dqs1n_tx_de-skew = <0x0a>;
		cs1_dqs0n_tx_de-skew = <0x09>;
		auto_pd_dis_freq = <0x42a>;
		phy_ddr4_odt = <0x02>;
		cs0_dq27_tx_de-skew = <0x07>;
		ddr3a11_ddr4a3_de-skew = <0x02>;
		cs1_dq20_tx_de-skew = <0x08>;
		cs1_dq26_rx_de-skew = <0x07>;
		cs0_dq31_tx_de-skew = <0x07>;
		cs0_dqs2_rx_de-skew = <0x09>;
		cs0_dq1_rx_de-skew = <0x0c>;
		cs0_dq12_rx_de-skew = <0x0a>;
		cs1_dq25_tx_de-skew = <0x07>;
		lpddr3_odt = <0xf0>;
		ddr3a13_ddr4a2_de-skew = <0x01>;
		cs1_dq30_rx_de-skew = <0x07>;
		cs1_dq4_rx_de-skew = <0x07>;
		cs0_dq0_tx_de-skew = <0x0a>;
		cs0_dq11_tx_de-skew = <0x08>;
		cs0_dq6_rx_de-skew = <0x0c>;
		cs0_dq17_rx_de-skew = <0x0a>;
		cs1_dqs0_rx_de-skew = <0x06>;
		ddr3_odt = <0x78>;
		cs1_dq10_rx_de-skew = <0x07>;
		cs1_dq3_tx_de-skew = <0x08>;
		phandle = <0x3c>;
		lpddr4_dq_odt = <0x28>;
		ddr3_odt_dis_freq = <0x64>;
		lpddr4_ca_odt = <0x28>;
		ddr3odt1_ddr4odt1_de-skew = <0x07>;
		cs1_dq9_rx_de-skew = <0x07>;
		ddr3ba1_ddr4a15_de-skew = <0x02>;
		cs0_dq5_tx_de-skew = <0x0a>;
		cs0_dq16_tx_de-skew = <0x09>;
		ddr3a10_ddr4cs0_de-skew = <0x02>;
		cs0_dq21_rx_de-skew = <0x0a>;
		lpddr4_odt_dis_freq = <0x320>;
		cs1_dq15_rx_de-skew = <0x07>;
		auto_sr_dis_freq = <0x320>;
		ddr3cs0_ddr4act_de-skew = <0x04>;
		cs1_dm1_rx_de-skew = <0x07>;
		cs1_dq8_tx_de-skew = <0x08>;
		cs0_dm3_rx_de-skew = <0x07>;
		cs0_dq20_tx_de-skew = <0x09>;
		cs0_dq26_rx_de-skew = <0x07>;
		phy_ddr3_dq_drv = <0x15>;
		cs1_dq14_tx_de-skew = <0x08>;
		phy_ddr3_ca_drv = <0x1b>;
		ddr3cs1_ddr4cs1_de-skew = <0x07>;
		cs1_dm0_tx_de-skew = <0x08>;
		cs0_dm2_tx_de-skew = <0x09>;
		cs0_dq25_tx_de-skew = <0x07>;
		ddr3a12_ddr4ba1_de-skew = <0x02>;
		ddr3_dll_dis_freq = <0x12c>;
		cs0_dq30_rx_de-skew = <0x07>;
		cs1_dq19_tx_de-skew = <0x08>;
		ddr3reset_ddr4reset_de-skew = <0x07>;
		ddr3a6_ddr4a7_de-skew = <0x02>;
		cs1_dq24_rx_de-skew = <0x07>;
		phy_ddr4_dq_drv = <0x16>;
		phy_ddr3_odt_dis_freq = <0x64>;
		phy_ddr4_ca_drv = <0x16>;
		phy_lpddr4_odt = <0x10>;
		ddr3a3_ddr4a6_de-skew = <0x03>;
		cs0_dqs0_rx_de-skew = <0x0a>;
		ddr3odt0_ddr4a14_de-skew = <0x04>;
		cs0_dq10_rx_de-skew = <0x0a>;
		cs1_dq23_tx_de-skew = <0x08>;
		cs1_dq29_rx_de-skew = <0x07>;
		ddr3ras_ddr4cke_de-skew = <0x04>;
		cs1_dq2_rx_de-skew = <0x07>;
		cs0_dq4_rx_de-skew = <0x0c>;
		cs0_dq15_rx_de-skew = <0x0a>;
		srpd_lite_idle = <0x00>;
		cs1_dq28_tx_de-skew = <0x07>;
		ddr3ba0_ddr4bg0_de-skew = <0x04>;
		ddr3a2_ddr4a4_de-skew = <0x02>;
		cs1_dq1_tx_de-skew = <0x08>;
		cs0_dqs3p_tx_de-skew = <0x0a>;
		cs1_dqs2p_tx_de-skew = <0x09>;
		phy_lpddr3_dq_drv = <0x16>;
		ddr3a14_ddr4a1_de-skew = <0x02>;
		ddr3_speed_bin = <0x15>;
		cs1_dq7_rx_de-skew = <0x07>;
		cs0_dq3_tx_de-skew = <0x0a>;
		cs0_dq14_tx_de-skew = <0x08>;
		phy_lpddr3_ca_drv = <0x16>;
		cs0_dq9_rx_de-skew = <0x0a>;
		ddr3a1_ddr4a9_de-skew = <0x02>;
		cs1_dqs3_rx_de-skew = <0x07>;
		cs1_dq13_rx_de-skew = <0x07>;
		cs0_dqs1p_tx_de-skew = <0x0a>;
		cs1_dq6_tx_de-skew = <0x08>;
		cs1_dqs0p_tx_de-skew = <0x09>;
		cs0_dm1_rx_de-skew = <0x0a>;
		ddr3a0_ddr4a10_de-skew = <0x03>;
		cs0_dq8_tx_de-skew = <0x08>;
		cs0_dq19_tx_de-skew = <0x09>;
	};

	mx9-sdio-pwrseq {
		pinctrl-names = "default";
		pinctrl-0 = <0x10c>;
		reset-gpios = <0x60 0x08 0x01>;
		compatible = "mmc-pwrseq-simple";
		post-power-on-delay-ms = <0xc8>;
		phandle = <0x107>;
	};

	usb@ff580000 {
		g-np-tx-fifo-size = <0x10>;
		phy-names = "usb2-phy";
		clock-names = "otg";
		g-tx-fifo-size = <0x100 0x80 0x80 0x40 0x20 0x10>;
		resets = <0x02 0x71>;
		interrupts = <0x00 0x17 0x04>;
		clocks = <0x02 0x14d>;
		g-rx-fifo-size = <0x118>;
		compatible = "rockchip,rk3328-usb\0rockchip,rk3066-usb\0snps,dwc2";
		status = "okay";
		phys = <0x5e>;
		reg = <0x00 0xff580000 0x00 0x40000>;
		phandle = <0xa9>;
		dr_mode = "host";
		reset-names = "dwc2";
	};

	i2s@ff010000 {
		clock-names = "i2s_clk\0i2s_hclk";
		interrupts = <0x00 0x1b 0x04>;
		clocks = <0x02 0x2a 0x02 0x138>;
		dma-names = "tx\0rx";
		#sound-dai-cells = <0x00>;
		compatible = "rockchip,rk3328-i2s\0rockchip,rk3066-i2s";
		status = "okay";
		reg = <0x00 0xff010000 0x00 0x1000>;
		phandle = <0x07>;
		dmas = <0x12 0x0e 0x12 0x0f>;
	};

	vcc-host-vbus {
		regulator-max-microvolt = <0x4c4b40>;
		pinctrl-names = "default";
		gpio = <0x74 0x00 0x00>;
		pinctrl-0 = <0x76>;
		regulator-always-on;
		enable-active-high;
		regulator-min-microvolt = <0x4c4b40>;
		regulator-name = "vcc_host_vbus";
		compatible = "regulator-fixed";
		phandle = <0x100>;
		vin-supply = <0x77>;
	};

	iommu@ff360480 {
		power-domains = <0x3e 0x05>;
		clock-names = "aclk\0iface";
		interrupts = <0x00 0x4a 0x04>;
		clocks = <0x02 0x8b 0x02 0x142>;
		#iommu-cells = <0x00>;
		compatible = "rockchip,iommu";
		status = "okay";
		reg = <0x00 0xff360480 0x00 0x40 0x00 0xff3604c0 0x00 0x40>;
		phandle = <0x40>;
	};

	i2c@ff170000 {
		pinctrl-names = "default";
		#address-cells = <0x01>;
		pinctrl-0 = <0x29>;
		clock-names = "i2c\0pclk";
		interrupts = <0x00 0x26 0x04>;
		clocks = <0x02 0x39 0x02 0xcf>;
		#size-cells = <0x00>;
		compatible = "rockchip,rk3328-i2c\0rockchip,rk3399-i2c";
		status = "disabled";
		reg = <0x00 0xff170000 0x00 0x1000>;
		phandle = <0x8b>;
	};

	vop@ff370000 {
		iommus = <0x41>;
		clock-names = "aclk_vop\0dclk_vop\0hclk_vop";
		resets = <0x02 0x85 0x02 0x86 0x02 0x87>;
		interrupts = <0x00 0x20 0x04>;
		clocks = <0x02 0x91 0x02 0x78 0x02 0x13b>;
		compatible = "rockchip,rk3328-vop";
		status = "okay";
		reg = <0x00 0xff370000 0x00 0x3efc>;
		phandle = <0x9d>;
		reset-names = "axi\0ahb\0dclk";

		port {
			phandle = <0x0d>;

			endpoint {
				remote-endpoint = <0x42>;
				phandle = <0x48>;
			};
		};
	};

	dfi@ff790000 {
		compatible = "rockchip,rk3328-dfi";
		status = "okay";
		rockchip,grf = <0x38>;
		reg = <0x00 0xff790000 0x00 0x400>;
		phandle = <0x39>;
	};

	ethernet@ff540000 {
		snps,txpbl = <0x04>;
		clock-names = "stmmaceth\0mac_clk_rx\0mac_clk_tx\0clk_mac_ref\0clk_mac_refout\0aclk_mac\0pclk_mac";
		resets = <0x02 0x63>;
		interrupts = <0x00 0x18 0x04>;
		clocks = <0x02 0x64 0x02 0x57 0x02 0x58 0x02 0x5a 0x02 0x59 0x02 0x96 0x02 0xdf>;
		compatible = "rockchip,rk3328-gmac";
		status = "disabled";
		rockchip,grf = <0x38>;
		tx-fifo-depth = <0x800>;
		interrupt-names = "macirq";
		rx-fifo-depth = <0x1000>;
		reg = <0x00 0xff540000 0x00 0x10000>;
		phandle = <0xa7>;
		reset-names = "stmmaceth";
	};

	vcc-phy-regulator {
		regulator-max-microvolt = <0x1b7740>;
		regulator-boot-on;
		regulator-always-on;
		regulator-min-microvolt = <0x1b7740>;
		regulator-name = "vcc_phy";
		compatible = "regulator-fixed";
		phandle = <0x5b>;
	};

	iommu@ff330200 {
		clock-names = "aclk\0iface";
		interrupts = <0x00 0x60 0x04>;
		clocks = <0x02 0x93 0x02 0xdd>;
		#iommu-cells = <0x00>;
		compatible = "rockchip,iommu";
		status = "okay";
		reg = <0x00 0xff330200 0x00 0x100>;
		phandle = <0x99>;
	};

	regulators {
		#address-cells = <0x01>;
		#size-cells = <0x00>;
		compatible = "simple-bus";

		regulator@1 {
			regulator-max-microvolt = <0x325aa0>;
			regulator-always-on;
			regulator-min-microvolt = <0x325aa0>;
			regulator-name = "vccio_3v3";
			compatible = "regulator-fixed";
			phandle = <0x1e>;
		};

		regulator@0 {
			regulator-max-microvolt = <0x1b7740>;
			regulator-always-on;
			regulator-min-microvolt = <0x1b7740>;
			regulator-name = "vccio_1v8";
			compatible = "regulator-fixed";
			phandle = <0x1f>;
		};
	};

	gmac-clkin {
		clock-output-names = "gmac_clkin";
		#clock-cells = <0x00>;
		clock-frequency = <0x7735940>;
		compatible = "fixed-clock";
		phandle = <0xff>;
	};

	timer {
		interrupts = <0x01 0x0d 0xf08 0x01 0x0e 0xf08 0x01 0x0b 0xf08 0x01 0x0a 0xf08>;
		compatible = "arm,armv8-timer";
	};

	iep@ff3a0000 {
		power-domains = <0x3e 0x05>;
		iommus = <0x43>;
		clock-names = "axi\0ahb";
		interrupts = <0x00 0x1f 0x04>;
		clocks = <0x02 0x9b 0x02 0x153>;
		compatible = "rockchip,rk3328-iep\0rockchip,rk3228-iep";
		interrupt-names = "iep";
		reg = <0x00 0xff3a0000 0x00 0x800>;
		phandle = <0x9f>;
	};

	sdio-pwrseq {
		pinctrl-names = "default";
		pinctrl-0 = <0x7e>;
		reset-gpios = <0x4d 0x12 0x01>;
		compatible = "mmc-pwrseq-simple";
		phandle = <0x53>;
	};

	usb@ff5c0000 {
		phy-names = "usb";
		resets = <0x02 0x76>;
		interrupts = <0x00 0x10 0x04>;
		clocks = <0x02 0x14e 0x4c>;
		compatible = "generic-ehci";
		status = "okay";
		phys = <0x5f>;
		reg = <0x00 0xff5c0000 0x00 0x10000>;
		phandle = <0xaa>;
		reset-names = "ehci";
	};

	aliases {
		i2c3 = "/i2c@ff180000";
		gpio0 = "/pinctrl/gpio@ff210000";
		i2c1 = "/i2c@ff160000";
		mmc3 = "/mmc@ff5f0000";
		mmc1 = "/mmc@ff510000";
		serial1 = "/serial@ff120000";
		gpio3 = "/pinctrl/gpio@ff240000";
		gpio1 = "/pinctrl/gpio@ff220000";
		i2c2 = "/i2c@ff170000";
		mmc4 = "/sdio@ff5f0000";
		i2c0 = "/i2c@ff150000";
		mmc2 = "/mmc@ff520000";
		mmc0 = "/mmc@ff500000";
		serial2 = "/serial@ff130000";
		serial0 = "/serial@ff110000";
		gpio2 = "/pinctrl/gpio@ff230000";
	};

	mmc@ff500000 {
		supports-sd;
		fifo-depth = <0x100>;
		pinctrl-names = "default";
		pinctrl-0 = <0x4e 0x4f 0x50 0x51>;
		clock-names = "biu\0ciu\0ciu-drive\0ciu-sample";
		cap-sd-highspeed;
		bus-width = <0x04>;
		no-sdio;
		resets = <0x02 0x6d>;
		card-detect-delay = <0x1f4>;
		interrupts = <0x00 0x0c 0x04>;
		clocks = <0x02 0x13d 0x02 0x21 0x02 0x4a 0x02 0x4e>;
		vmmc-supply = <0x52>;
		compatible = "rockchip,rk3328-dw-mshc\0rockchip,rk3288-dw-mshc";
		status = "okay";
		disable-wp;
		reg = <0x00 0xff500000 0x00 0x4000>;
		phandle = <0xa4>;
		max-frequency = <0x8f0d180>;
		cap-mmc-highspeed;
		reset-names = "reset";
		cd-gpios = <0x4d 0x05 0x01>;
	};

	iommu@ff3a0800 {
		power-domains = <0x3e 0x05>;
		clock-names = "aclk\0iface";
		interrupts = <0x00 0x1f 0x04>;
		clocks = <0x02 0x9b 0x02 0x153>;
		#iommu-cells = <0x00>;
		compatible = "rockchip,iommu";
		interrupt-names = "iep_mmu";
		reg = <0x00 0xff3a0800 0x00 0x40>;
		phandle = <0x43>;
	};

	mmc@ff5f0000 {
		supports-sd;
		fifo-depth = <0x100>;
		pinctrl-names = "default";
		#address-cells = <0x01>;
		pinctrl-0 = <0x61 0x62 0x63 0x64>;
		clock-names = "biu\0ciu\0ciu-drive\0ciu-sample";
		cap-sd-highspeed;
		bus-width = <0x04>;
		no-sdio;
		resets = <0x02 0x68>;
		card-detect-delay = <0x1f4>;
		interrupts = <0x00 0x04 0x04>;
		clocks = <0x02 0x140 0x02 0x1f 0x02 0x4d 0x02 0x51>;
		#size-cells = <0x00>;
		vmmc-supply = <0x52>;
		compatible = "rockchip,rk3328-dw-mshc\0rockchip,rk3288-dw-mshc";
		status = "disabled";
		disable-wp;
		reg = <0x00 0xff5f0000 0x00 0x4000>;
		phandle = <0xac>;
		max-frequency = <0x8f0d180>;
		cap-mmc-highspeed;
		reset-names = "reset";
		cd-gpios = <0x60 0x01 0x01>;
	};

	serial@ff110000 {
		reg-io-width = <0x04>;
		pinctrl-names = "default";
		pinctrl-0 = <0x20 0x21 0x22>;
		clock-names = "baudclk\0apb_pclk";
		interrupts = <0x00 0x37 0x04>;
		clocks = <0x02 0x26 0x02 0xd2>;
		dma-names = "tx\0rx";
		compatible = "rockchip,rk3328-uart\0snps,dw-apb-uart";
		status = "okay";
		reg = <0x00 0xff110000 0x00 0x100>;
		phandle = <0x86>;
		dmas = <0x12 0x02 0x12 0x03>;
		reg-shift = <0x02>;
	};

	adc@ff280000 {
		vref-supply = <0x1f>;
		clock-names = "saradc\0apb_pclk";
		resets = <0x02 0x56>;
		interrupts = <0x00 0x50 0x04>;
		clocks = <0x02 0x25 0x02 0xea>;
		#io-channel-cells = <0x01>;
		compatible = "rockchip,rk3328-saradc\0rockchip,rk3399-saradc";
		status = "okay";
		reg = <0x00 0xff280000 0x00 0x100>;
		phandle = <0x73>;
		reset-names = "saradc-apb";
	};

	chosen {
		u-boot,version = "2022.07_armbian-2022.07-Se092-P621f-H28b4-V67df-Bbf55-R448a";
		linux,initrd-end = <0x00 0x7df22d1b>;
		bootargs = "root=UUID=b82a1580-8fe4-456f-abe4-a32ca973b55e rootwait rootfstype=ext4 splash=verbose console=ttyS2,1500000 console=tty1 consoleblank=0 loglevel=1 ubootpart=77c81bb8-01 usb-storage.quirks=0x2537:0x1066:u,0x2537:0x1068:u apparmor=1 security=apparmor systemd.unified_cgroup_hierarchy=0  cgroup_enable=cpuset cgroup_memory=1 cgroup_enable=memory swapaccount=1";
		linux,initrd-start = <0x00 0x7c359000>;
		stdout-path = "serial2:1500000n8";
	};

	i2s@ff020000 {
		clock-names = "i2s_clk\0i2s_hclk";
		interrupts = <0x00 0x1c 0x04>;
		clocks = <0x02 0x2b 0x02 0x139>;
		dma-names = "tx\0rx";
		#sound-dai-cells = <0x00>;
		compatible = "rockchip,rk3328-i2s\0rockchip,rk3066-i2s";
		status = "disabled";
		reg = <0x00 0xff020000 0x00 0x1000>;
		phandle = <0x83>;
		dmas = <0x12 0x00 0x12 0x01>;
	};

	dmc@ff780000 {
		clock-names = "dmc_clk";
		clocks = <0x02 0x40>;
		center-supply = <0x3b>;
		ddr_timing = <0x3c>;
		devfreq-events = <0x39>;
		compatible = "rockchip,rk3328-dmc";
		status = "disabled";
		reg = <0x00 0xff780000 0x00 0x400>;
		phandle = <0x94>;
		operating-points-v2 = <0x3a>;
		#cooling-cells = <0x02>;
	};

	hdmi@ff3c0000 {
		reg-io-width = <0x04>;
		pinctrl-names = "default";
		phy-names = "hdmi";
		pinctrl-0 = <0x45 0x46 0x47>;
		clock-names = "iahb\0isfr\0cec";
		interrupts = <0x00 0x23 0x04>;
		clocks = <0x02 0xe7 0x02 0x46 0x02 0x1e>;
		#sound-dai-cells = <0x00>;
		compatible = "rockchip,rk3328-dw-hdmi";
		status = "okay";
		rockchip,grf = <0x38>;
		phys = <0x44>;
		reg = <0x00 0xff3c0000 0x00 0x20000>;
		phandle = <0x0f>;

		ports {
			#address-cells = <0x01>;
			#size-cells = <0x00>;

			port@0 {
				reg = <0x00>;
				phandle = <0xa0>;

				endpoint {
					remote-endpoint = <0x48>;
					phandle = <0x42>;
				};
			};

			port@1 {
				reg = <0x01>;
				phandle = <0xa1>;
			};
		};
	};

	i2c@ff180000 {
		pinctrl-names = "default";
		#address-cells = <0x01>;
		pinctrl-0 = <0x2a>;
		clock-names = "i2c\0pclk";
		interrupts = <0x00 0x27 0x04>;
		clocks = <0x02 0x3a 0x02 0xd0>;
		#size-cells = <0x00>;
		compatible = "rockchip,rk3328-i2c\0rockchip,rk3399-i2c";
		status = "disabled";
		reg = <0x00 0xff180000 0x00 0x1000>;
		phandle = <0x8c>;
	};

	ir-receiver {
		pinctrl-names = "default";
		pinctrl-0 = <0x7d>;
		compatible = "gpio-ir-receiver";
		gpios = <0x7c 0x02 0x01>;
	};

	ethernet@ff550000 {
		phy-supply = <0x5b>;
		phy-mode = "rmii";
		snps,txpbl = <0x04>;
		clock-names = "stmmaceth\0mac_clk_rx\0mac_clk_tx\0clk_mac_ref\0aclk_mac\0pclk_mac\0clk_macphy";
		assigned-clocks = <0x02 0x65>;
		assigned-clock-parents = <0x02 0x54>;
		assigned-clock-rate = <0x2faf080>;
		resets = <0x02 0x62>;
		interrupts = <0x00 0x15 0x04>;
		clocks = <0x02 0x54 0x02 0x53 0x02 0x53 0x02 0x55 0x02 0x95 0x02 0xde 0x02 0x56>;
		clock_in_out = "output";
		compatible = "rockchip,rk3328-gmac";
		status = "okay";
		rockchip,grf = <0x38>;
		tx-fifo-depth = <0x800>;
		interrupt-names = "macirq";
		rx-fifo-depth = <0x1000>;
		reg = <0x00 0xff550000 0x00 0x10000>;
		rx_delay = <0x10>;
		phandle = <0xa8>;
		phy-handle = <0x5a>;
		reset-names = "stmmaceth";
		tx_delay = <0x30>;

		mdio {
			#address-cells = <0x01>;
			#size-cells = <0x00>;
			compatible = "snps,dwmac-mdio";

			ethernet-phy@0 {
				pinctrl-names = "default";
				pinctrl-0 = <0x5c 0x5d>;
				resets = <0x02 0x64>;
				clocks = <0x02 0x56>;
				compatible = "ethernet-phy-id1234.d400\0ethernet-phy-ieee802.3-c22";
				phy-is-integrated;
				reg = <0x00>;
				phandle = <0x5a>;
			};
		};
	};

	video-codec@ff350000 {
		power-domains = <0x3e 0x08>;
		iommus = <0x3f>;
		clock-names = "aclk\0hclk";
		vcodec-supply = <0x3b>;
		interrupts = <0x00 0x09 0x04>;
		clocks = <0x02 0x8f 0x02 0x146>;
		compatible = "rockchip,rk3328-vpu";
		status = "okay";
		interrupt-names = "vdpu";
		reg = <0x00 0xff350000 0x00 0x800>;
		phandle = <0x9b>;
	};

	fd628_dev {
		fd628_gpio_clk = <0x7c 0x10 0x00>;
		compatible = "fd628_dev";
		status = "okay";
		fd628_gpio_dat = <0x7c 0x0f 0x00>;
	};

	vdd-arm {
		regulator-max-microvolt = <0x155cc0>;
		regulator-boot-on;
		regulator-always-on;
		regulator-min-microvolt = <0xe7ef0>;
		regulator-name = "vdd_arm";
		regulator-ramp-delay = <0x30d4>;
		compatible = "pwm-regulator";
		regulator-settling-time-up-us = <0xfa>;
		phandle = <0x06>;
		pwms = <0x79 0x00 0x1388 0x01>;
		pwm-supply = <0x77>;
	};

	pdm@ff040000 {
		pinctrl-names = "default\0sleep";
		pinctrl-0 = <0x14 0x15 0x16 0x17 0x18>;
		clock-names = "pdm_clk\0pdm_hclk";
		clocks = <0x02 0x3d 0x02 0x152>;
		dma-names = "rx";
		compatible = "rockchip,pdm";
		pinctrl-1 = <0x19 0x1a 0x1b 0x1c 0x1d>;
		status = "disabled";
		reg = <0x00 0xff040000 0x00 0x1000>;
		phandle = <0x84>;
		dmas = <0x12 0x10>;
	};

	sdmmc-regulator {
		regulator-max-microvolt = <0x325aa0>;
		pinctrl-names = "default";
		regulator-boot-on;
		gpio = <0x74 0x1e 0x01>;
		pinctrl-0 = <0x75>;
		regulator-always-on;
		regulator-min-microvolt = <0x325aa0>;
		regulator-name = "vcc_sd";
		compatible = "regulator-fixed";
		phandle = <0x52>;
		vin-supply = <0x1e>;
	};

	cpus {
		#address-cells = <0x02>;
		#size-cells = <0x00>;

		cpu@1 {
			d-cache-line-size = <0x40>;
			cpu-supply = <0x06>;
			clocks = <0x02 0x06>;
			i-cache-line-size = <0x40>;
			cpu-idle-states = <0x03>;
			device_type = "cpu";
			compatible = "arm,cortex-a53";
			dynamic-power-coefficient = <0x78>;
			d-cache-size = <0x8000>;
			next-level-cache = <0x05>;
			i-cache-size = <0x8000>;
			reg = <0x00 0x01>;
			enable-method = "psci";
			phandle = <0x0a>;
			d-cache-sets = <0x80>;
			operating-points-v2 = <0x04>;
			i-cache-sets = <0x100>;
			#cooling-cells = <0x02>;
		};

		l2-cache {
			cache-size = <0x40000>;
			cache-level = <0x02>;
			cache-sets = <0x100>;
			cache-unified;
			compatible = "cache";
			cache-line-size = <0x40>;
			phandle = <0x05>;
		};

		idle-states {
			entry-method = "psci";

			cpu-sleep {
				entry-latency-us = <0x78>;
				local-timer-stop;
				exit-latency-us = <0xfa>;
				arm,psci-suspend-param = <0x10000>;
				compatible = "arm,idle-state";
				phandle = <0x03>;
				min-residency-us = <0x384>;
			};
		};

		cpu@2 {
			d-cache-line-size = <0x40>;
			cpu-supply = <0x06>;
			clocks = <0x02 0x06>;
			i-cache-line-size = <0x40>;
			cpu-idle-states = <0x03>;
			device_type = "cpu";
			compatible = "arm,cortex-a53";
			dynamic-power-coefficient = <0x78>;
			d-cache-size = <0x8000>;
			next-level-cache = <0x05>;
			i-cache-size = <0x8000>;
			reg = <0x00 0x02>;
			enable-method = "psci";
			phandle = <0x0b>;
			d-cache-sets = <0x80>;
			operating-points-v2 = <0x04>;
			i-cache-sets = <0x100>;
			#cooling-cells = <0x02>;
		};

		cpu@0 {
			d-cache-line-size = <0x40>;
			cpu-supply = <0x06>;
			clocks = <0x02 0x06>;
			i-cache-line-size = <0x40>;
			cpu-idle-states = <0x03>;
			device_type = "cpu";
			compatible = "arm,cortex-a53";
			dynamic-power-coefficient = <0x78>;
			d-cache-size = <0x8000>;
			next-level-cache = <0x05>;
			i-cache-size = <0x8000>;
			reg = <0x00 0x00>;
			enable-method = "psci";
			phandle = <0x09>;
			d-cache-sets = <0x80>;
			operating-points-v2 = <0x04>;
			i-cache-sets = <0x100>;
			#cooling-cells = <0x02>;
		};

		cpu@3 {
			d-cache-line-size = <0x40>;
			cpu-supply = <0x06>;
			clocks = <0x02 0x06>;
			i-cache-line-size = <0x40>;
			cpu-idle-states = <0x03>;
			device_type = "cpu";
			compatible = "arm,cortex-a53";
			dynamic-power-coefficient = <0x78>;
			d-cache-size = <0x8000>;
			next-level-cache = <0x05>;
			i-cache-size = <0x8000>;
			reg = <0x00 0x03>;
			enable-method = "psci";
			phandle = <0x0c>;
			d-cache-sets = <0x80>;
			operating-points-v2 = <0x04>;
			i-cache-sets = <0x100>;
			#cooling-cells = <0x02>;
		};
	};

	spdif-out {
		#sound-dai-cells = <0x00>;
		compatible = "linux,spdif-dit";
		status = "okay";
		phandle = <0x11>;
	};

	__symbols__ {
		i2c3 = "/i2c@ff180000";
		vdd_arm = "/vdd-arm";
		i2s1_sdio1 = "/pinctrl/i2s1/i2s1-sdio1";
		pdmm0_sdi3 = "/pinctrl/pdm-0/pdmm0-sdi3";
		usb30_host_drv = "/pinctrl/usb3/usb30-host-drv";
		pcfg_pull_none_4ma = "/pinctrl/pcfg-pull-none-4ma";
		i2s2m1_mclk = "/pinctrl/i2s2-1/i2s2m1-mclk";
		sdio_host_wake_ext = "/pinctrl/wireless-wlan/sdio-host-wake-ext";
		i2s2m1_lrcktx = "/pinctrl/i2s2-1/i2s2m1-lrcktx";
		i2s2m0_lrckrx = "/pinctrl/i2s2-0/i2s2m0-lrckrx";
		pcfg_input_high = "/pinctrl/pcfg-input-high";
		spdif_sound = "/spdif-sound";
		pdmm0_sdi1_sleep = "/pinctrl/pdm-0/pdmm0-sdi1-sleep";
		spdif_out = "/spdif-out";
		hdmi_in_vop = "/hdmi@ff3c0000/ports/port@0/endpoint";
		sdmmc0ext_cmd = "/pinctrl/sdmmc0ext/sdmmc0ext-cmd";
		gpio0 = "/pinctrl/gpio@ff210000";
		saradc = "/adc@ff280000";
		vcc_host_vbus = "/vcc-host-vbus";
		emmc_rstnout = "/pinctrl/emmc/emmc-rstnout";
		sdmmc1_pins = "/pinctrl/sdmmc1/sdmmc1-pins";
		spi0m0_tx = "/pinctrl/spi0-0/spi0m0-tx";
		crypto = "/crypto@ff060000";
		dfi = "/dfi@ff790000";
		pinctrl = "/pinctrl";
		i2s2m1_lrckrx = "/pinctrl/i2s2-1/i2sm1-lrckrx";
		pdmm0_clk = "/pinctrl/pdm-0/pdmm0-clk";
		i2s1 = "/i2s@ff010000";
		pdm = "/pdm@ff040000";
		vdd_logic = "/vdd-log";
		uart2m1_xfer = "/pinctrl/uart2-1/uart2m1-xfer";
		hdmi_cec = "/pinctrl/hdmi_pin/hdmi-cec";
		i2c1 = "/i2c@ff160000";
		fephyled_linkm1 = "/pinctrl/gmac2phy/fephyled-linkm1";
		sdmmc1_bus1 = "/pinctrl/sdmmc1/sdmmc1-bus1";
		pdmm0_sdi1 = "/pinctrl/pdm-0/pdmm0-sdi1";
		u2phy_otg = "/syscon@ff450000/usb2phy@100/otg-port";
		pdmm0_fsync = "/pinctrl/pdm-0/pdmm0-fsync";
		sdmmc0ext_bus4 = "/pinctrl/sdmmc0ext/sdmmc0ext-bus4";
		sdmmc0_clk = "/pinctrl/sdmmc0/sdmmc0-clk";
		emmc_cmd = "/pinctrl/emmc/emmc-cmd";
		pcfg_pull_none = "/pinctrl/pcfg-pull-none";
		otp_out = "/pinctrl/tsadc/otp-out";
		pdmm0_clk_sleep = "/pinctrl/pdm-0/pdmm0-clk-sleep";
		dmac = "/dma-controller@ff1f0000";
		spi0m0_rx = "/pinctrl/spi0-0/spi0m0-rx";
		spi0m1_clk = "/pinctrl/spi0-1/spi0m1-clk";
		fephyled_duplex = "/pinctrl/gmac2phy/fephyled-duplex";
		target = "/thermal-zones/soc-thermal/trips/trip-point1";
		i2s1_mclk = "/pinctrl/i2s1/i2s1-mclk";
		vcc_sys = "/vcc-sys";
		i2s2m0_sleep = "/pinctrl/i2s2-0/i2s2m0-sleep";
		dvp_d2d9_m1 = "/pinctrl/cif-1/dvp-d2d9-m1";
		i2s2m0_sdo = "/pinctrl/i2s2-0/i2s2m0-sdo";
		gpu = "/gpu@ff300000";
		spi0 = "/spi@ff190000";
		iep = "/iep@ff3a0000";
		vcc_otg_vbus = "/vcc-otg-vbus";
		mx9_sdio_pwrseq = "/mx9-sdio-pwrseq";
		pwm0_pin = "/pinctrl/pwm0/pwm0-pin";
		hdmi_hpd = "/pinctrl/hdmi_pin/hdmi-hpd";
		usb_host0_ohci = "/usb@ff5d0000";
		sdmmc0_dectn = "/pinctrl/sdmmc0/sdmmc0-dectn";
		dmc = "/dmc@ff780000";
		i2s2m0_mclk = "/pinctrl/i2s2-0/i2s2m0-mclk";
		sdmmc1_cmd = "/pinctrl/sdmmc1/sdmmc1-cmd";
		logic_leakage = "/efuse@ff260000/logic-leakage@19";
		usbdrd3 = "/usb@ff600000";
		tsadc_pin = "/pinctrl/tsadc_pin/tsadc-pin";
		sdmmc0_pins = "/pinctrl/sdmmc0/sdmmc0-pins";
		gpio_led = "/gpio-leds";
		pcfg_input = "/pinctrl/pcfg-input";
		dmc_opp_table = "/dmc-opp-table";
		spi0m0_cs0 = "/pinctrl/spi0-0/spi0m0-cs0";
		sdmmc0m1_pwren = "/pinctrl/sdmmc0-1/sdmmc0m1-pwren";
		ir_int = "/pinctrl/ir/ir-int";
		uart2m0_xfer = "/pinctrl/uart2-0/uart2m0-xfer";
		sdmmc0ext_clk = "/pinctrl/sdmmc0ext/sdmmc0ext-clk";
		clk_32k_out = "/pinctrl/clk_32k/clk-32k-out";
		xin32k = "/xin32k";
		sdmmc0_bus1 = "/pinctrl/sdmmc0/sdmmc0-bus1";
		adc_keys = "/adc-keys";
		cpu0_opp_table = "/opp_table0";
		i2c3_xfer = "/pinctrl/i2c3/i2c3-xfer";
		power = "/syscon@ff100000/power-controller";
		i2c3_pins = "/pinctrl/i2c3/i2c3-pins";
		pwm3 = "/pwm@ff1b0030";
		gmac_clkin = "/gmac-clkin";
		vdec_mmu = "/iommu@ff360480";
		emmc_clk = "/pinctrl/emmc/emmc-clk";
		cru = "/clock-controller@ff440000";
		spdifm1_tx = "/pinctrl/spdif-1/spdifm1-tx";
		cpu3 = "/cpus/cpu@3";
		pdmm0_sdi2_sleep = "/pinctrl/pdm-0/pdmm0-sdi2-sleep";
		uart2 = "/serial@ff130000";
		pcfg_pull_up_12ma = "/pinctrl/pcfg-pull-up-12ma";
		u2phy = "/syscon@ff450000/usb2phy@100";
		pcfg_output_low = "/pinctrl/pcfg-output-low";
		sdio_pwrseq = "/sdio-pwrseq";
		vdec = "/video-codec@ff360000";
		gic = "/interrupt-controller@ff811000";
		sdmmc1_clk = "/pinctrl/sdmmc1/sdmmc1-clk";
		sdmmc1_pwren = "/pinctrl/sdmmc1/sdmmc1-pwren";
		uart0_rts_pin = "/pinctrl/uart0/uart0-rts-pin";
		pwm1 = "/pwm@ff1b0010";
		threshold = "/thermal-zones/soc-thermal/trips/trip-point0";
		vpu = "/video-codec@ff350000";
		spi0m2_tx = "/pinctrl/spi0-2/spi0m2-tx";
		spi0m2_clk = "/pinctrl/spi0-2/spi0m2-clk";
		emmc_bus1 = "/pinctrl/emmc/emmc-bus1";
		otp_pin = "/pinctrl/tsadc/otp-pin";
		vop_out_hdmi = "/vop@ff370000/port/endpoint";
		xin24m = "/xin24m";
		i2s2m1_sdo = "/pinctrl/i2s2-1/i2s2m1-sdo";
		pcfg_pull_up_2ma = "/pinctrl/pcfg-pull-up-2ma";
		tsadc = "/tsadc@ff250000";
		uart0_cts = "/pinctrl/uart0/uart0-cts";
		gpio3 = "/pinctrl/gpio@ff240000";
		sdmmc0_wrprt = "/pinctrl/sdmmc0/sdmmc0-wrprt";
		pwm1_pin = "/pinctrl/pwm1/pwm1-pin";
		gpu_opp_table = "/opp-table-gpu";
		pcfg_output_high = "/pinctrl/pcfg-output-high";
		cpu1 = "/cpus/cpu@1";
		i2s2m1_sleep = "/pinctrl/i2s2-1/i2s2m1-sleep";
		uart0 = "/serial@ff110000";
		i2c2_xfer = "/pinctrl/i2c2/i2c2-xfer";
		pmic_int_l = "/pinctrl/pmic/pmic-int-l";
		i2s2m0_sdi = "/pinctrl/i2s2-0/i2s2m0-sdi";
		fephyled_speed10 = "/pinctrl/gmac2phy/fephyled-speed10";
		sdmmc1_dectn = "/pinctrl/sdmmc1/sdmmc1-dectn";
		spi0m2_rx = "/pinctrl/spi0-2/spi0m2-rx";
		usb3phy = "/usb3-phy@ff460000";
		ddr_timing = "/ddr_timing";
		sdmmc1_bus4 = "/pinctrl/sdmmc1/sdmmc1-bus4";
		i2s1_sdio2 = "/pinctrl/i2s1/i2s1-sdio2";
		emmc = "/mmc@ff520000";
		mx9_sdmmc0ext_dectn = "/pinctrl/mx9pro-sdmmc0ext/mx9-sdmmc0ext-dectn";
		efuse_id = "/efuse@ff260000/id@7";
		vop_mmu = "/iommu@ff373f00";
		iep_mmu = "/iommu@ff3a0800";
		usb2phy_grf = "/syscon@ff450000";
		spdif = "/spdif@ff030000";
		mx9_sdmmc0ext_cmd = "/pinctrl/mx9pro-sdmmc0ext/mx9-sdmmc0ext-cmd";
		spi0m1_cs0 = "/pinctrl/spi0-1/spi0m1-cs0";
		wifi_enable_h = "/pinctrl/sdio-pwrseq/wifi-enable-h";
		fephyled_rxm1 = "/pinctrl/gmac2phy/fephyled-rxm1";
		cpu_leakage = "/efuse@ff260000/cpu-leakage@17";
		i2s1_sdo = "/pinctrl/i2s1/i2s1-sdo";
		gpio1 = "/pinctrl/gpio@ff220000";
		tsadc_int = "/pinctrl/tsadc_pin/tsadc-int";
		wdt = "/watchdog@ff1a0000";
		hdmi_out = "/hdmi@ff3c0000/ports/port@1";
		working_led = "/pinctrl/leds/working-led";
		mx9_pcfg_pull_up_4ma = "/pinctrl/mx9-pcfg-pull-up-4ma";
		i2s2 = "/i2s@ff020000";
		grf_gpio = "/syscon@ff100000/gpio";
		hdmii2c_xfer = "/pinctrl/hdmi_i2c/hdmii2c-xfer";
		i2c2 = "/i2c@ff170000";
		pdmm0_sdi2 = "/pinctrl/pdm-0/pdmm0-sdi2";
		emmc_bus8 = "/pinctrl/emmc/emmc-bus8";
		usb_host0_ehci = "/usb@ff5c0000";
		vcc_io = "/regulators/regulator@1";
		pcfg_pull_up_8ma = "/pinctrl/pcfg-pull-up-8ma";
		i2c1_xfer = "/pinctrl/i2c1/i2c1-xfer";
		pcfg_pull_down_4ma = "/pinctrl/pcfg-pull-down-4ma";
		pwmir_pin = "/pinctrl/pwmir/pwmir-pin";
		u2phy_host = "/syscon@ff450000/usb2phy@100/host-port";
		usb20_otg = "/usb@ff580000";
		pdmm0_sdi3_sleep = "/pinctrl/pdm-0/pdmm0-sdi3-sleep";
		pdmm0_fsync_sleep = "/pinctrl/pdm-0/pdmm0-fsync-sleep";
		usb20_host_drv = "/pinctrl/usb2/usb20-host-drv";
		sdmmc0_bus4 = "/pinctrl/sdmmc0/sdmmc0-bus4";
		pcfg_pull_none_2ma = "/pinctrl/pcfg-pull-none-2ma";
		emmc_pwren = "/pinctrl/emmc/emmc-pwren";
		vop_out = "/vop@ff370000/port";
		sdmmc = "/mmc@ff500000";
		i2s0 = "/i2s@ff000000";
		i2c0 = "/i2c@ff150000";
		soc_thermal = "/thermal-zones/soc-thermal";
		pdmm0_sdi0 = "/pinctrl/pdm-0/pdmm0-sdi0";
		spdifm0_tx = "/pinctrl/spdif-0/spdifm0-tx";
		uart0_rts = "/pinctrl/uart0/uart0-rts";
		pcfg_pull_none_12ma = "/pinctrl/pcfg-pull-none-12ma";
		io_domains = "/syscon@ff100000/io-domains";
		h265e_mmu = "/iommu@ff330200";
		sdmmc0ext_dectn = "/pinctrl/sdmmc0ext/sdmmc0ext-dectn";
		uart1_cts = "/pinctrl/uart1/uart1-cts";
		gmac2io = "/ethernet@ff540000";
		pwm2_pin = "/pinctrl/pwm2/pwm2-pin";
		mx9_sdmmc0ext_clk = "/pinctrl/mx9pro-sdmmc0ext/mx9-sdmmc0ext-clk";
		sdmmc0m0_pin = "/pinctrl/sdmmc0-0/sdmmc0m0-pin";
		spi0m0_cs1 = "/pinctrl/spi0-0/spi0m0-cs1";
		sdio = "/mmc@ff510000";
		sdmmc1_wrprt = "/pinctrl/sdmmc1/sdmmc1-wrprt";
		codec = "/codec@ff410000";
		i2s2m1_sdi = "/pinctrl/i2s2-1/i2s2m1-sdi";
		dvp_d2d9_m0 = "/pinctrl/cif-0/dvp-d2d9-m0";
		i2s2m1_sclk = "/pinctrl/i2s2-1/i2s2m1-sclk";
		vepu_mmu = "/iommu@ff340800";
		efuse_cpu_version = "/efuse@ff260000/cpu-version@1a";
		hdmiphy = "/phy@ff430000";
		sdmmc0ext_pins = "/pinctrl/sdmmc0ext/sdmmc0ext-pins";
		vop = "/vop@ff370000";
		usb3phy_pipe = "/usb3-phy@ff460000/pipe-port@ff478000";
		sdio_ext = "/sdio@ff5f0000";
		spi0m1_tx = "/pinctrl/spi0-1/spi0m1-tx";
		i2c0_xfer = "/pinctrl/i2c0/i2c0-xfer";
		vcc_18 = "/regulators/regulator@0";
		emmc_bus4 = "/pinctrl/emmc/emmc-bus4";
		spi0m2_cs0 = "/pinctrl/spi0-2/spi0m2-cs0";
		sdmmc0ext_bus1 = "/pinctrl/sdmmc0ext/sdmmc0ext-bus1";
		soc_crit = "/thermal-zones/soc-thermal/trips/soc-crit";
		vcc_sd = "/sdmmc-regulator";
		pdmm0_sdi0_sleep = "/pinctrl/pdm-0/pdmm0-sdi0-sleep";
		pcfg_pull_down = "/pinctrl/pcfg-pull-down";
		pcfg_pull_up = "/pinctrl/pcfg-pull-up";
		vpu_mmu = "/iommu@ff350800";
		spi0m1_rx = "/pinctrl/spi0-1/spi0m1-rx";
		uart1_xfer = "/pinctrl/uart1/uart1-xfer";
		pcfg_pull_none_8ma = "/pinctrl/pcfg-pull-none-8ma";
		i2s1_sdi = "/pinctrl/i2s1/i2s1-sdi";
		pcfg_pull_up_4ma = "/pinctrl/pcfg-pull-up-4ma";
		vcc_phy = "/vcc-phy-regulator";
		phy = "/ethernet@ff550000/mdio/ethernet-phy@0";
		fephyled_txm1 = "/pinctrl/gmac2phy/fephyled-txm1";
		mx9_sdmmc0ext_bus4 = "/pinctrl/mx9pro-sdmmc0ext/mx9-sdmmc0ext-bus4";
		gmac2phy = "/ethernet@ff550000";
		mx9_pcfg_pull_none = "/pinctrl/mx9-pcfg-pull-none";
		i2s1_lrcktx = "/pinctrl/i2s1/i2s1-lrcktx";
		i2s1_sclk = "/pinctrl/i2s1/i2s1-sclk";
		pwm2 = "/pwm@ff1b0020";
		CPU_SLEEP = "/cpus/idle-states/cpu-sleep";
		display_subsystem = "/display-subsystem";
		i2s2m0_sclk = "/pinctrl/i2s2-0/i2s2m0-sclk";
		efuse = "/efuse@ff260000";
		i2s1_sleep = "/pinctrl/i2s1/i2s1-sleep";
		cpu2 = "/cpus/cpu@2";
		spi0m0_clk = "/pinctrl/spi0-0/spi0m0-clk";
		uart1 = "/serial@ff120000";
		hdmi = "/hdmi@ff3c0000";
		i2s1_lrckrx = "/pinctrl/i2s1/i2s1-lrckrx";
		rgmiim1_pins = "/pinctrl/gmac-1/rgmiim1-pins";
		hdmi_in = "/hdmi@ff3c0000/ports/port@0";
		analog_sound = "/analog-sound";
		l2_cache = "/cpus/l2-cache";
		i2s1_sdio3 = "/pinctrl/i2s1/i2s1-sdio3";
		uart1_rts = "/pinctrl/uart1/uart1-rts";
		grf = "/syscon@ff100000";
		mx9_pcfg_pull_none_4ma = "/pinctrl/mx9-pcfg-pull-none-4ma";
		sdio_host_wake = "/pinctrl/wireless-wlan/sdio-host-wake";
		sdmmc0_cmd = "/pinctrl/sdmmc0/sdmmc0-cmd";
		mx9_wifi_enable_h = "/pinctrl/mx9-wifi-enable-h";
		sdmmc0ext_wrprt = "/pinctrl/sdmmc0ext/sdmmc0ext-wrprt";
		usb3phy_utmi = "/usb3-phy@ff460000/utmi-port@ff470000";
		rmiim1_pins = "/pinctrl/gmac-1/rmiim1-pins";
		pwm0 = "/pwm@ff1b0000";
		hdmi_sound = "/hdmi-sound";
		sdmmc0m1_pin = "/pinctrl/sdmmc0-1/sdmmc0m1-pin";
		spi0m1_cs1 = "/pinctrl/spi0-1/spi0m1-cs1";
		uart0_xfer = "/pinctrl/uart0/uart0-xfer";
		uart1_rts_pin = "/pinctrl/uart1/uart1-rts-pin";
		gpio2 = "/pinctrl/gpio@ff230000";
		sdmmc0m0_pwren = "/pinctrl/sdmmc0-0/sdmmc0m0-pwren";
		cpu0 = "/cpus/cpu@0";
		spdifm2_tx = "/pinctrl/spdif-2/spdifm2-tx";
		rga = "/rga@ff390000";
		i2s2m0_lrcktx = "/pinctrl/i2s2-0/i2s2m0-lrcktx";
		sdmmc_ext = "/mmc@ff5f0000";
	};

	clock-controller@ff440000 {
		#reset-cells = <0x01>;
		clock-names = "xin24m";
		assigned-clocks = <0x02 0x78 0x02 0x3d 0x02 0x1e 0x02 0x26 0x02 0x27 0x02 0x28 0x02 0x88 0x02 0x89 0x02 0x8e 0x02 0x85 0x02 0x83 0x02 0x8a 0x02 0x8c 0x02 0x8d 0x02 0x41 0x02 0x42 0x02 0x44 0x02 0x43 0x02 0x22 0x02 0x5c 0x02 0x35 0x02 0x06 0x02 0x04 0x02 0x03 0x02 0x88 0x02 0x148 0x02 0xd8 0x02 0x89 0x02 0x134 0x02 0xe6 0x02 0x87 0x02 0x1e>;
		assigned-clock-parents = <0x02 0x7a 0x02 0x01 0x02 0x04 0x4a 0x4a 0x4a>;
		assigned-clock-rates = <0x00 0x3a98000 0x00 0x16e3600 0x16e3600 0x16e3600 0xe4e1c0 0xe4e1c0 0x11e1a300 0x5f5e100 0x17d78400 0x5f5e100 0x2faf080 0x5f5e100 0x5f5e100 0x5f5e100 0x2faf080 0x2faf080 0x2faf080 0x2faf080 0x16e3600 0x23c34600 0x1d4c0000 0x47868c00 0x8f0d180 0x47868c0 0x47868c0 0x8f0d180 0x47868c0 0x47868c0 0x1dcd6500 0x8000>;
		clocks = <0x4a>;
		#clock-cells = <0x01>;
		compatible = "rockchip,rk3328-cru";
		rockchip,grf = <0x38>;
		reg = <0x00 0xff440000 0x00 0x1000>;
		phandle = <0x02>;
	};

	spi@ff190000 {
		pinctrl-names = "default";
		#address-cells = <0x01>;
		pinctrl-0 = <0x2b 0x2c 0x2d 0x2e>;
		clock-names = "spiclk\0apb_pclk";
		interrupts = <0x00 0x31 0x04>;
		clocks = <0x02 0x20 0x02 0xd1>;
		#size-cells = <0x00>;
		dma-names = "tx\0rx";
		compatible = "rockchip,rk3328-spi\0rockchip,rk3066-spi";
		status = "disabled";
		reg = <0x00 0xff190000 0x00 0x1000>;
		phandle = <0x8d>;
		dmas = <0x12 0x08 0x12 0x09>;
	};

	pwm@ff1b0030 {
		pinctrl-names = "default";
		pinctrl-0 = <0x32>;
		clock-names = "pwm\0pclk";
		clocks = <0x02 0x3c 0x02 0xd6>;
		#pwm-cells = <0x03>;
		compatible = "rockchip,rk3328-pwm";
		status = "disabled";
		reg = <0x00 0xff1b0030 0x00 0x10>;
		phandle = <0x90>;
	};

	usb@ff5d0000 {
		phy-names = "usb";
		interrupts = <0x00 0x11 0x04>;
		clocks = <0x02 0x14e 0x4c>;
		compatible = "generic-ohci";
		status = "okay";
		phys = <0x5f>;
		reg = <0x00 0xff5d0000 0x00 0x10000>;
		phandle = <0xab>;
	};

	watchdog@ff1a0000 {
		interrupts = <0x00 0x28 0x04>;
		clocks = <0x02 0xec>;
		compatible = "rockchip,rk3328-wdt\0snps,dw-wdt";
		reg = <0x00 0xff1a0000 0x00 0x100>;
		phandle = <0x8e>;
	};

	codec@ff410000 {
		clock-names = "pclk\0mclk";
		clocks = <0x02 0xeb 0x02 0x2a>;
		mute-gpios = <0x49 0x00 0x01>;
		#sound-dai-cells = <0x00>;
		compatible = "rockchip,rk3328-codec";
		status = "okay";
		rockchip,grf = <0x38>;
		reg = <0x00 0xff410000 0x00 0x1000>;
		phandle = <0x08>;
	};

	pwm@ff1b0020 {
		pinctrl-names = "default";
		pinctrl-0 = <0x31>;
		clock-names = "pwm\0pclk";
		clocks = <0x02 0x3c 0x02 0xd6>;
		#pwm-cells = <0x03>;
		compatible = "rockchip,rk3328-pwm";
		status = "disabled";
		reg = <0x00 0xff1b0020 0x00 0x10>;
		phandle = <0x8f>;
	};

	mmc@ff510000 {
		fifo-depth = <0x100>;
		pinctrl-names = "default";
		#address-cells = <0x01>;
		supports-sdio;
		pinctrl-0 = <0x54 0x55 0x56>;
		clock-names = "biu\0ciu\0ciu-drive\0ciu-sample";
		cap-sd-highspeed;
		bus-width = <0x04>;
		non-removable;
		resets = <0x02 0x6e>;
		cap-sdio-irq;
		interrupts = <0x00 0x0d 0x04>;
		clocks = <0x02 0x13e 0x02 0x22 0x02 0x4b 0x02 0x4f>;
		num-slots = <0x01>;
		#size-cells = <0x00>;
		keep-power-in-suspend;
		compatible = "rockchip,rk3328-dw-mshc\0rockchip,rk3288-dw-mshc";
		status = "disabled";
		disable-wp;
		mmc-pwrseq;
		reg = <0x00 0xff510000 0x00 0x4000>;
		phandle = <0xa5>;
		max-frequency = <0x8f0d180>;
		reset-names = "reset";
	};

	dmc-opp-table {
		compatible = "operating-points-v2";
		phandle = <0x3a>;

		opp-850000000 {
			opp-microvolt = <0x100590 0x100590 0x124f80>;
			opp-hz = <0x00 0x32a9f880>;
			status = "disabled";
		};

		opp-786000000 {
			opp-microvolt = <0x100590 0x100590 0x124f80>;
			opp-hz = <0x00 0x2ed96880>;
		};

		opp-933000000 {
			opp-microvolt = <0x10c8e0 0x10c8e0 0x124f80>;
			opp-hz = <0x00 0x379c7340>;
			status = "disabled";
		};

		opp-666000000 {
			opp-microvolt = <0xfa3e8 0xfa3e8 0x124f80>;
			opp-hz = <0x00 0x27b25a80>;
		};

		opp-600000000 {
			opp-microvolt = <0xf4240 0xf4240 0x124f80>;
			opp-hz = <0x00 0x23c34600>;
		};

		opp-1066000000 {
			opp-microvolt = <0x118c30 0x118c30 0x124f80>;
			opp-hz = <0x00 0x3f89de80>;
			status = "disabled";
		};

		opp-800000000 {
			opp-microvolt = <0x100590 0x100590 0x124f80>;
			opp-hz = <0x00 0x2faf0800>;
			status = "disabled";
		};
	};

	vcc-sys {
		regulator-max-microvolt = <0x4c4b40>;
		regulator-boot-on;
		regulator-always-on;
		regulator-min-microvolt = <0x4c4b40>;
		regulator-name = "vcc_sys";
		compatible = "regulator-fixed";
		phandle = <0x77>;
	};

	pwm@ff1b0010 {
		pinctrl-names = "default";
		pinctrl-0 = <0x30>;
		clock-names = "pwm\0pclk";
		clocks = <0x02 0x3c 0x02 0xd6>;
		#pwm-cells = <0x03>;
		compatible = "rockchip,rk3328-pwm";
		status = "okay";
		reg = <0x00 0xff1b0010 0x00 0x10>;
		phandle = <0x7a>;
	};

	interrupt-controller@ff811000 {
		#address-cells = <0x00>;
		interrupts = <0x01 0x09 0xf04>;
		compatible = "arm,gic-400";
		#interrupt-cells = <0x03>;
		reg = <0x00 0xff811000 0x00 0x1000 0x00 0xff812000 0x00 0x2000 0x00 0xff814000 0x00 0x2000 0x00 0xff816000 0x00 0x2000>;
		phandle = <0x01>;
		interrupt-controller;
	};

	memory {
		device_type = "memory";
		reg = <0x00 0x200000 0x00 0x7fe00000>;
	};

	serial@ff120000 {
		reg-io-width = <0x04>;
		pinctrl-names = "default";
		pinctrl-0;
		clock-names = "baudclk\0apb_pclk";
		interrupts = <0x00 0x38 0x04>;
		clocks = <0x02 0x27 0x02 0xd3>;
		dma-names = "tx\0rx";
		compatible = "rockchip,rk3328-uart\0snps,dw-apb-uart";
		status = "okay";
		reg = <0x00 0xff120000 0x00 0x100>;
		phandle = <0x87>;
		dmas = <0x12 0x04 0x12 0x05>;
		reg-shift = <0x02>;
	};

	pwm@ff1b0000 {
		pinctrl-names = "default";
		pinctrl-0 = <0x2f>;
		clock-names = "pwm\0pclk";
		clocks = <0x02 0x3c 0x02 0xd6>;
		#pwm-cells = <0x03>;
		compatible = "rockchip,rk3328-pwm";
		status = "okay";
		reg = <0x00 0xff1b0000 0x00 0x10>;
		phandle = <0x79>;
	};
};
